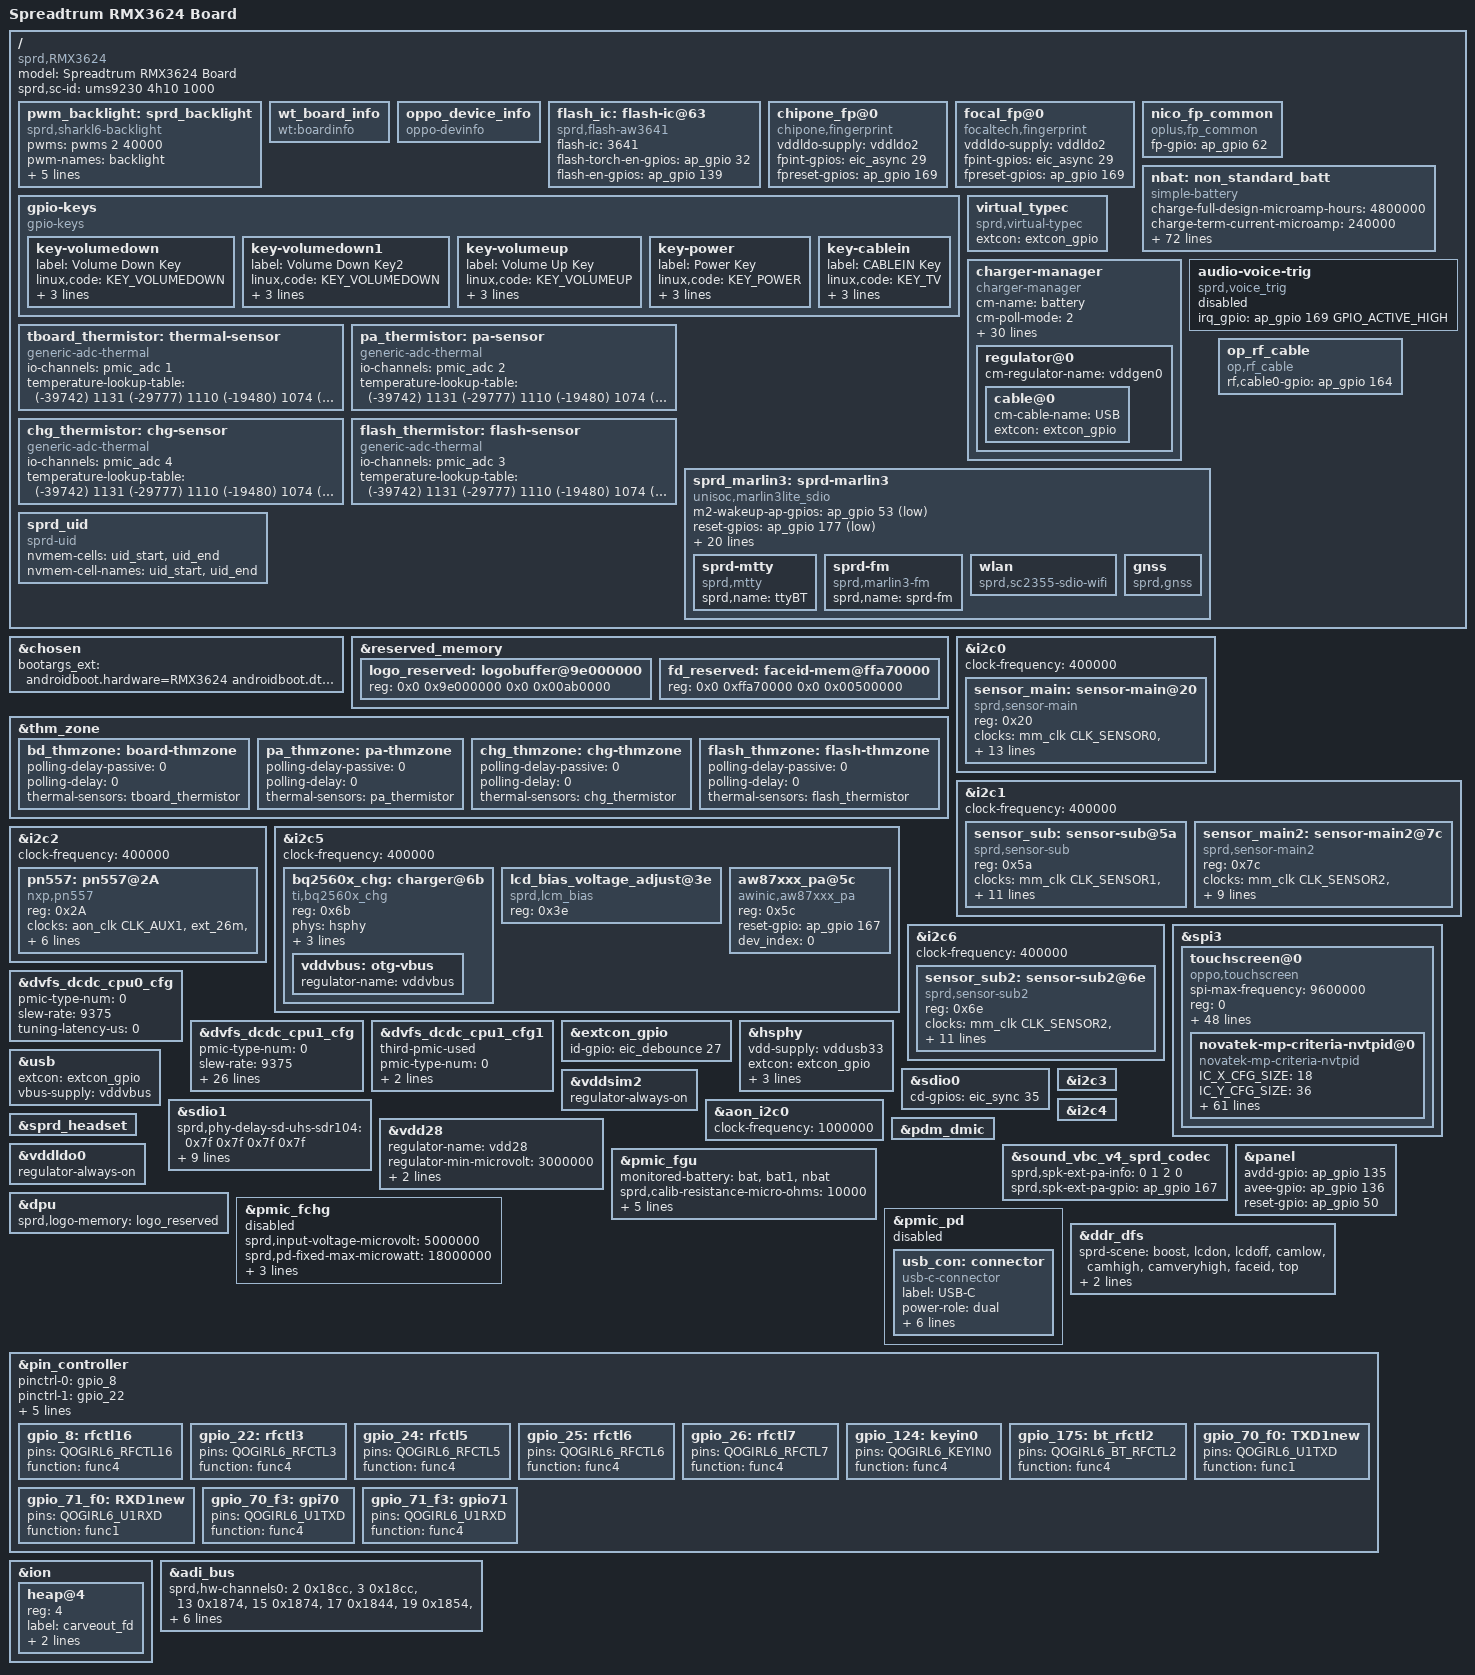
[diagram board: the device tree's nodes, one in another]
/dts-v1/;
/plugin/;
#include <dt-bindings/input/input.h>
#include <dt-bindings/gpio/gpio.h>
#include <dt-bindings/interrupt-controller/arm-gic.h>
#include <dt-bindings/clock/sprd,ums9230-clk.h>
#include <dt-bindings/mfd/sprd,sc2730-regs.h>
#include <dt-bindings/mfd/sprd,sc2730-mask.h>
#include <dt-bindings/usb/pd.h>
/*wangcong@DISPLAY.LCD 2022.06.10 modify for beidouB bring up lcd*/
#include "lcd/lcd_ili9882q_txd_mipi_hd.dtsi"
#include "lcd/lcd_icnl9911c_cw_mipi_hd.dtsi"
/*wangcong@DISPLAY.LCD 2022.06.10 modify for beidouB bring up lcd*/
/*niuhang@DISPLAY.LCD 2022.11.1 modify for beidouE bring up lcd*/
#include "lcd/lcd_icnl9911c_lc_mipi_hd.dtsi"
/*niuhang@DISPLAY.LCD 2022.11.1 modify for beidouE bring up lcd*/
/*bsp.zhoulingyun 2022.04.04 modify for bring up lcd tm*/
#include "lcd/lcd_NT36672C_csot_mipi_hd.dtsi"
#include "lcd/lcd_NT36672C_tm_mipi_hd.dtsi"
#include "lcd/lcd_g40396_truly_mipi_fhd.dtsi"
#include "lcd/lcd_dummy_mipi.dtsi"
#include "battery/RMX3624_OPLUS_LWN_4V45_5000mah.dtsi"
#include "battery/RMX3624_OPLUS_ATL_4V45_5000mah.dtsi"
/ {

	model = "Spreadtrum RMX3624 Board";

	compatible = "sprd,RMX3624";

	sprd,sc-id = "ums9230 4h10 1000";
	fragment {
		target-path = "/";
		__overlay__ {
			#address-cells = <2>;
			#size-cells = <2>;

			pwm_backlight: sprd_backlight {
				compatible = "sprd,sharkl6-backlight";
				pwms = <&pwms 2 40000>;
				pwm-names = "backlight";
				sprd,max-brightness-level = <924>;
				default-brightness-level = <262>;
				sprd,brightness-scale = <1023>;
				brightness-levels = <
							  0   3   4   5   6   7
					  8   9  10  11  12  13  14  16  17  18
					 19  20  21  22  23  24  25  26  27  28
					 29  31  33  35  37  39  41  43  45  47
					 48  50  52  54  56  58  60  62  64  67
					 69  72  74  76  78  80  82  84  86  88
					 90  92  94  96  98 100 102 104 107 109
					112 114 116 118 120 122 124 126 128 130
					132 134 136 138 140 142 144 147 149 151
					154 156 158 160 162 164 166 168 170 172
					175 178 181 184 187 190 193 196 199 203
					205 208 211 214 217 220 223 226 229 234
					237 240 243 247 250 253 256 259 263 266
					269 270 274 277 280 283 287 290 294 297
					300 303 307 310 314 318 325 329 334 339
					340 343 347 350 354 358 365 369 374 380
					382 385 389 392 396 400 407 411 416 422
					426 430 434 438 442 446 452 457 460 464
					470 474 480 486 492 498 504 508 512 516
					522 527 532 536 540 545 550 555 561 568
					574 579 584 589 594 600 605 610 615 620
					625 630 635 641 647 652 657 662 667 673
					688 694 700 706 712 716 720 725 730 735
					740 746 752 758 764 770 776 782 790 798
					803 810 817 825 832 840 845 850 855 861
					866 872 878 884 890 896 903 911 918 924
				>;
			};
			wt_board_info: wt_board_info {
				compatible = "wt:boardinfo";
				status = "okay";
			};

			oppo_device_info: oppo_device_info {
				compatible = "oppo-devinfo";
				status = "okay";
			};

			flash_ic: flash-ic@63 {
				compatible = "sprd,flash-aw3641";
				flash-ic = <3641>;
				flash-torch-en-gpios = <&ap_gpio 32 0>;
				flash-en-gpios = <&ap_gpio 139 0>;
				status = "okay";
			};
			chipone_fp@0 {
				compatible = "chipone,fingerprint";
				vddldo-supply = <&vddldo2>;
				fpint-gpios = <&eic_async 29 0 >;
				fpreset-gpios = <&ap_gpio 169 0 >;
			};

			focal_fp@0 {
				compatible = "focaltech,fingerprint";
				vddldo-supply = <&vddldo2>;
				fpint-gpios = <&eic_async 29 0 >;
				fpreset-gpios = <&ap_gpio 169 0 >;
			};

			nico_fp_common {
				compatible = "oplus,fp_common";
				fp-gpio = <&ap_gpio 62 0 >;
			};

			gpio-keys {
				compatible = "gpio-keys";

				key-volumedown {
					label = "Volume Down Key";
					linux,code = <KEY_VOLUMEDOWN>;
					gpios = <&ap_gpio 124 GPIO_ACTIVE_LOW>;
					debounce-interval = <2>;
					wakeup-source;
				};

				key-volumedown1 {
					label = "Volume Down Key2";
					linux,code = <KEY_VOLUMEDOWN>;
					gpios = <&ap_gpio 126 GPIO_ACTIVE_LOW>;
					debounce-interval = <2>;
					wakeup-source;
				};

				key-volumeup {
					label = "Volume Up Key";
					linux,code = <KEY_VOLUMEUP>;
					gpios = <&pmic_eic 4 GPIO_ACTIVE_HIGH>;
					debounce-interval = <2>;
					wakeup-source;
				};

				key-power {
					label = "Power Key";
					linux,code = <KEY_POWER>;
					gpios = <&pmic_eic 1 GPIO_ACTIVE_LOW>;
					debounce-interval = <2>;
					wakeup-source;
				};
/*wt_jiangshaokang,20220605,Add cable key detect for modem*/
				key-cablein {
					label = "CABLEIN Key";
					linux,code = <KEY_TV>;
					gpios = <&ap_gpio 164 GPIO_ACTIVE_HIGH>;
					debounce-interval = <2>;
					wakeup-source;
				};
/*wt_jiangshaokang,20220605,Add cable key detect for modem*/
			};


			nbat: non_standard_batt {
				compatible = "simple-battery";
				charge-full-design-microamp-hours = <4800000>;
				charge-term-current-microamp = <240000>;
				constant-charge-voltage-max-microvolt = <4432000>;
				factory-internal-resistance-micro-ohms = <130000>;
				voltage-min-design-microvolt = <3450000>;
				fullbatt-voltage = <4395000 4395000>;
				fullbatt-current = <260000>;
				fullbatt-track-end-vol = <4390000>;
				fullbatt-track-end-cur = <270000>;
				first-calib-voltage = <3580000>;
				first-calib-capacity = <50>;

				ir-cv-offset-microvolt = <100000>;
				ir-rc-micro-ohms = <20000>;
				ir-us-upper-limit-microvolt = <4500000>;

				ocv-capacity-celsius = <20>;
				ocv-capacity-table-0 = <4380000 100>, <4317000 95>, <4258000 90>,
							<4200000 85>, <4145000 80>, <4092000 75>,
							<4047000 70>, <3990000 65>, <3955000 60>,
							<3900000 55>, <3861000 50>, <3834000 45>,
							<3813000 40>, <3796000 35>, <3783000 30>,
							<3770000 25>, <3752000 20>, <3730000 15>,
							<3698000 10>, <3687000 5>, <3400000 0>;
				 voltage-temp-table = <1404000 650>, <1307000 700>, <1203000 750>,
							<1095000 800>, <986000 850>, <878000 900>,
							<775000 950>, <678000 1000>, <590000 1050>,
							<510000 1100>, <440000 1150>, <378000 1200>,
							<324000 1250>, <278000 1300>, <238000 1350>,
							<204000 1400>, <175000 1450>, <150000 1500>,
							<129000 1550>, <111000 1600>, <96000 1650>,
							<83000 1700>, <73000 1750>, <63000 1800>,
							<55000 1850>, <48000 1900>, <42000 1950>;
				capacity-temp-table = <45 100>, <25 100>, <10 98>, <0 93>, <(-10) 85>, <(-20) 64>;
				resistance-temp-table = <45 100>, <25 100>, <10 546>, <0 769>, <(-10) 892>, <(-20) 923>;
				charge-sdp-current-microamp = <500000 600000>;
				charge-dcp-current-microamp = <2000000 3250000>;
				charge-cdp-current-microamp = <1500000 3250000>;
				charge-unknown-current-microamp = <1200000 1200000>;
				dcp-jeita-temp-table = <900 901 0 4435000 0 4435000>,
							<1000 1030 1000000 4435000 750000 4180000>,
							<1050 1080 2250000 4435000 1250000 4435000>,
							<1120 1150 2250000 4435000 2250000 4435000>,
							<1160 1190 3250000 4435000 2250000 4180000>,
							<1450 1420 3250000 4435000 3250000 4435000>,
							<1530 1500 1250000 4130000 1250000 4130000>;
				sdp-jeita-temp-table = <900 901 0 4435000 0 4435000>,
							<1000 1030 600000 4435000 600000 4180000>,
							<1050 1080 600000 4435000 600000 4435000>,
							<1120 1150 600000 4435000 600000 4435000>,
							<1160 1190 600000 4435000 600000 4180000>,
							<1450 1420 600000 4435000 600000 4435000>,
							<1530 1500 600000 4130000 600000 4130000>;
				cdp-jeita-temp-table = <900 901 0 4435000 0 4435000>,
							<1000 1030 1000000 4435000 750000 4180000>,
							<1050 1080 2250000 4435000 1250000 4180000>,
							<1120 1150 2250000 4435000 2250000 4435000>,
							<1160 1190 3250000 4435000 2250000 4180000>,
							<1450 1420 3250000 4435000 3250000 4435000>,
							<1530 1500 1250000 4130000 1250000 4130000>;
				unknown-jeita-temp-table = <900 901 0 4435000 0 4180000>,
							<1000 1030 480000 4435000 480000 4180000>,
							<1050 1080 480000 4435000 480000 4435000>,
							<1120 1150 1000000 4435000 1000000 4435000>,
							<1160 1190 1200000 4435000 1200000 4435000>,
							<1450 1420 1200000 4435000 1200000 4435000>,
							<1530 1500 1000000 4130000 1000000 4130000>;
				force-jeita-status = <5>;
			};

			virtual_typec: virtual_typec {
				compatible = "sprd,virtual-typec";
				extcon = <&extcon_gpio>;
				status = "okay";
			};

			charger-manager {
				compatible = "charger-manager";
				cm-name = "battery";
				cm-poll-mode = <2>;
				cm-poll-interval = <5000>;
				cm-battery-stat = <2>;

				cm-fullbatt-vchkdrop-ms = <30000>;
				cm-fullbatt-vchkdrop-volt = <60000>;
				cm-fullbatt-capacity = <100>;
				/*Charge pump target charge current*/
				cm-cp-taper-current = <1000000>;

				cm-num-chargers = <1>;

				cm-chargers = "bq2560x_charger";
				cm-fuel-gauge = "sc27xx-fgu";

				/* in deci centigrade */
				cm-battery-cold = <200>;
				cm-battery-cold-in-minus;
				cm-battery-hot = <800>;
				cm-battery-temp-diff = <100>;

				/* Allow charging for 6hr */
				cm-charging-max = <72000000>;
				/* recovery charging after stop charging 45min */
				cm-discharging-max = <2700000>;

				/* the interval to feed charger watchdog */
				cm-wdt-interval = <60>;

				/* drop voltage in microVolts to allow shutdown */
				cm-shutdown-voltage = <3300000>;

				/* when 99% of the time is exceeded, it will be forced to 100% */
				cm-tickle-time-out = <1500>;

				/* how much time to allow capacity change */
				cm-one-cap-time = <15>;
				cm-thermal-zone = "board-thmzone";
				/* when the safe charging voltage is exceeded, stop charging */
				cm-charge-voltage-max = <5800000>;
				/* drop voltage in microVolts to restart charging */
				cm-charge-voltage-drop = <350000>;

				//cm-cap-remap-table = <1 2 3>, <2 3 2>, <98 99 2>, <99 100 3>;
				cm-cap-remap-table = <99 100 3>;

				monitored-battery = <&bat &bat1 &nbat>;
				cm-capacity-track;
	
				io-channels = <&pmic_adc 6>;
				io-channel-names = "bat-id-vol";

				pinctrl-names = "gpio_70_f0", "gpio_71_f0", "gpio_70_f3", "gpio_71_f3";
				pinctrl-0 = <&gpio_70_f0>;
				pinctrl-1 = <&gpio_71_f0>;
				pinctrl-2 = <&gpio_70_f3>;
				pinctrl-3 = <&gpio_71_f3>;

				regulator@0 {
					cm-regulator-name = "vddgen0";
					cable@0 {
						cm-cable-name = "USB";
						extcon = <&extcon_gpio>;
					};
				};
			};

			tboard_thermistor: thermal-sensor {
				compatible = "generic-adc-thermal";
				#thermal-sensor-cells = <0>;
				io-channels = <&pmic_adc 1>;
				io-channel-names = "sensor-channel";
				temperature-lookup-table = <
					(-39742) 1131
					(-29777) 1110
					(-19480) 1074
					(-4679) 983
					10110 838
					24805 654
					44922 413
					54903 316
					64895 238
					74884 178
					84883 133
					94883 100
					104880 75
					114889 57
					124872 43 >;
			};

			pa_thermistor: pa-sensor {
				compatible = "generic-adc-thermal";
				#thermal-sensor-cells = <0>;
				io-channels = <&pmic_adc 2>;
				io-channel-names = "sensor-channel";
				temperature-lookup-table = <
					(-39742) 1131
					(-29777) 1110
					(-19480) 1074
					(-4679) 983
					10110 838
					24805 654
					44922 413
					54903 316
					64895 238
					74884 178
					84883 133
					94883 100
					104880 75
					114889 57
					124872 43 >;
			};

			chg_thermistor: chg-sensor {
				compatible = "generic-adc-thermal";
				#thermal-sensor-cells = <0>;
				io-channels = <&pmic_adc 4>;
				io-channel-names = "sensor-channel";
				temperature-lookup-table = <
					(-39742) 1131
					(-29777) 1110
					(-19480) 1074
					(-4679) 983
					10110 838
					24805 654
					44922 413
					54903 316
					64895 238
					74884 178
					84883 133
					94883 100
					104880 75
					114889 57
					124872 43 >;
			};
			flash_thermistor: flash-sensor {
				compatible = "generic-adc-thermal";
				#thermal-sensor-cells = <0>;
				io-channels = <&pmic_adc 3>;
				io-channel-names = "sensor-channel";
				temperature-lookup-table = <
					(-39742) 1131
					(-29777) 1110
					(-19480) 1074
					(-4679) 983
					10110 838
					24805 654
					44922 413
					54903 316
					64895 238
					74884 178
					84883 133
					94883 100
					104880 75
					114889 57
					124872 43 >;
			};

			audio-voice-trig {
				status = "disable";
				compatible = "sprd,voice_trig";
				irq_gpio = <&ap_gpio 169 GPIO_ACTIVE_HIGH>;
			};

			sprd_marlin3: sprd-marlin3 {
				compatible = "unisoc,marlin3lite_sdio";
				m2-wakeup-ap-gpios = <&ap_gpio 53 GPIO_ACTIVE_LOW>;
				reset-gpios = <&ap_gpio 177 GPIO_ACTIVE_LOW>;
				enable-gpios = <&ap_gpio 116 GPIO_ACTIVE_LOW>;
				m2-to-ap-irq-gpios = <&ap_gpio 52 GPIO_ACTIVE_LOW>;
				avdd12-supply = <&vddwcn>;
				avdd33-supply = <&vddwifipa>;
				dcxo18-supply = <&vddsim2>;
				xtal-26m-clk-type = "TSX";
				clock-names = "clk_32k","source","enable";
				clocks = <&aon_clk CLK_AUX2>,
					 <&ext_32k>,
					 <&aonapb_gate CLK_AUX2_EB>;

				extcon = <&sdio1>;
				sdhci-name = <&sdio1>;
				sprd,btwf-file-name = "/dev/block/by-name/wcnmodem";
				sprd,gnss-file-name = "/vendor/firmware/gnssmodem.bin";
				adma-tx;
				adma-rx;

				/*
				 * bound parameter:
				 * [0]:addr offset, [1]:mask, [2]:unboundval, [3]:boundval
				 */
				/*avdd12-parent-bound-chip = <REG_ANA_SLP_DCDC_PD_CTRL MASK_ANA_SLP_DCDCGEN1_PD_EN 0x0 MASK_ANA_SLP_DCDCGEN1_PD_EN>;*/
				avdd12-bound-wbreq = <REG_ANA_LDO_XTL_EN10 MASK_ANA_LDO_VDDWCN_EXT_XTL3_EN 0x0 MASK_ANA_LDO_VDDWCN_EXT_XTL3_EN>;
				avdd33-bound-wbreq = <REG_ANA_LDO_XTL_EN11 MASK_ANA_LDO_VDDWIFIPA_EXT_XTL3_EN 0x0 MASK_ANA_LDO_VDDWIFIPA_EXT_XTL3_EN>;

				sprd-mtty {
					compatible = "sprd,mtty";
					sprd,name = "ttyBT";
				};

				sprd-fm {
					compatible = "sprd,marlin3-fm";
					sprd,name = "sprd-fm";
				};

				wlan {
					compatible = "sprd,sc2355-sdio-wifi";
				};

				gnss {
					compatible = "sprd,gnss";
				};
			};

			/*Used to check the RF antenna*/
			op_rf_cable {
				compatible = "op,rf_cable";
				status = "okay";
				rf,cable0-gpio = <&ap_gpio 164 GPIO_ACTIVE_HIGH>;
			};

			sprd_uid {
				compatible = "sprd-uid";
				nvmem-cells = <&uid_start>, <&uid_end>;
				nvmem-cell-names = "uid_start", "uid_end";
			};

		};
	};
};

&chosen {
	bootargs_ext = "androidboot.hardware=RMX3624 androidboot.dtbo_idx=0";
};

&reserved_memory {
	#address-cells = <2>;
	#size-cells = <2>;
	logo_reserved: logobuffer@9e000000{
		reg = <0x0 0x9e000000 0x0 0x00ab0000>;
	};

	fd_reserved: faceid-mem@ffa70000 {
		reg = <0x0 0xffa70000 0x0 0x00500000>;
	};
};

&thm_zone {

	bd_thmzone: board-thmzone {
		polling-delay-passive = <0>;
		polling-delay = <0>;
		thermal-sensors = <&tboard_thermistor>;
	};

	pa_thmzone: pa-thmzone {
		polling-delay-passive = <0>;
		polling-delay = <0>;
		thermal-sensors = <&pa_thermistor>;
	};

	chg_thmzone: chg-thmzone {
		polling-delay-passive = <0>;
		polling-delay = <0>;
		thermal-sensors = <&chg_thermistor>;
	};
	flash_thmzone: flash-thmzone {
		polling-delay-passive = <0>;
		polling-delay = <0>;
		thermal-sensors = <&flash_thermistor>;
	};

};

&i2c0 {
	status = "okay";
	clock-frequency = <400000>;
	#address-cells = <1>;
	#size-cells = <0>;

	sensor_main: sensor-main@20 {
		compatible = "sprd,sensor-main";
		reg = <0x20>;
		clock-names = "clk_src","sensor_eb",
			"clk_96m","clk_76m8",
			"clk_48m","clk_26m";
		clocks = <&mm_clk CLK_SENSOR0>,<&mm_gate CLK_MM_SENSOR0_EB>,
				<&pll1 CLK_TWPLL_96M>,<&pll1 CLK_TWPLL_76M8>,
				<&pll1 CLK_TWPLL_48M>,<&ext_26m>;
		vddio-supply = <&vddcamio>;
		vddcama-supply = <&vddcama0>;
		vddcamd-supply = <&vddcamd0>;
		vddcammot-supply = <&vddcammot>;
		dvdd-gpios = <&ap_gpio 146 0>;
		reset-gpios = <&ap_gpio 45 0>;
		power-down-gpios = <&ap_gpio 47 0>;
		sprd,phyid = <0>;
		csi = <&csi0>;
		power-domains = <&mm_domain>;
	};
};

&i2c1 {
	status = "okay";
	clock-frequency = <400000>;
	#address-cells = <1>;
	#size-cells = <0>;

	sensor_sub: sensor-sub@5a {
		compatible = "sprd,sensor-sub";
		reg = <0x5a>;
		clock-names = "clk_src","sensor_eb",
			"clk_96m","clk_76m8",
			"clk_48m","clk_26m";
		clocks = <&mm_clk CLK_SENSOR1>,<&mm_gate CLK_MM_SENSOR1_EB>,
				<&pll1 CLK_TWPLL_96M>,<&pll1 CLK_TWPLL_76M8>,
				<&pll1 CLK_TWPLL_48M>,<&ext_26m>;
		vddio-supply = <&vddcamio>;
		vddcama-supply = <&vddcama1>;
		vddcamd-supply = <&vddcamd0>;
		reset-gpios = <&ap_gpio 44 0>;
		power-down-gpios = <&ap_gpio 47 0>;
		sprd,phyid = <2>;
		csi = <&csi0>;
		power-domains = <&mm_domain>;
	};

	sensor_main2: sensor-main2@7c {
		compatible = "sprd,sensor-main2";
		reg = <0x7c>;
		clock-names = "clk_src","sensor_eb",
			"clk_96m","clk_76m8",
			"clk_48m","clk_26m";
		clocks = <&mm_clk CLK_SENSOR2>,<&mm_gate CLK_MM_SENSOR2_EB>,
				<&pll1 CLK_TWPLL_96M>,<&pll1 CLK_TWPLL_76M8>,
				<&pll1 CLK_TWPLL_48M>,<&ext_26m>;
		vddio-supply = <&vddcamio>;
		vddcama-supply = <&vddcama1>;
		reset-gpios = <&ap_gpio 47 0>;
		sprd,phyid = <4>;
		csi = <&csi2>;
		power-domains = <&mm_domain>;
	};


};

&i2c2 {
        status = "okay";
        clock-frequency = <400000>;
        #address-cells = <1>;
        #size-cells = <0>;
        pn557: pn557@2A {
                compatible = "nxp,pn557";
                reg = <0x2A>;
                clock-names = "pn557_clk","source","enable";
                clocks = <&aon_clk CLK_AUX1>, <&ext_26m>, <&aonapb_gate CLK_AUX1_EB>;
                bb-clocks = "beidouB";
                nxp,ven-gpio = <&ap_gpio 134 0>;
                nxp,irq-gpio = <&ap_gpio 30 0>;
                nxp,firm-gpio = <&ap_gpio 16 0>;
                nxp,clkreq-gpio = <&ap_gpio 15 0>;
        };
};

&i2c5 {
	status = "okay";
	clock-frequency = <400000>;
	#address-cells = <1>;
	#size-cells = <0>;

	bq2560x_chg: charger@6b {
		compatible = "ti,bq2560x_chg";
		reg = <0x6b>;
		phys = <&hsphy>;
		monitored-battery = <&bat &bat1 &nbat>;
		extcon = <&extcon_gpio>;
		/*pd-extcon-enable;*/
		irq-gpio = <&ap_gpio 115 GPIO_ACTIVE_LOW>;
		vddvbus:otg-vbus {
			regulator-name = "vddvbus";
		};
	};
	/*
	bq2597x_chg: charger@65 {
		compatible = "ti,bq2597x-standalone";
		reg = <0x65>;
		irq-gpio = <&ap_gpio 126 GPIO_ACTIVE_LOW>;

		ti,bq2597x,bus-therm-disable = <1>;
		ti,bq2597x,regulation-disable = <1>;

		ti,bq2597x,bat-ovp-threshold = <4400>;
		ti,bq2597x,bat-ovp-alarm-threshold = <4340>;
		ti,bq2597x,bat-ocp-threshold = <5500>;
		ti,bq2597x,bat-ocp-alarm-threshold = <5000>;
		ti,bq2597x,bus-ovp-threshold = <11500>;
		ti,bq2597x,bus-ovp-alarm-threshold = <10500>;
		ti,bq2597x,bus-ocp-threshold = <3000>;
		ti,bq2597x,bus-ocp-alarm-threshold = <2700>;
		ti,bq2597x,bat-ucp-alarm-threshold = <1000>;
		ti,bq2597x,bat-therm-threshold = <0x15>;
		ti,bq2597x,bus-therm-threshold = <0x15>;
		ti,bq2597x,die-therm-threshold = <0xc8>;
		ti,bq2597x,ac-ovp-threshold = <11>;
		ti,bq2597x,sense-resistor-mohm = <5>;
		ti,bq2597x,adc-sample-bits = <13>;
		ti,bq2597x,ibat-regulation-threshold = <300>;
		ti,bq2597x,vbat-regulation-threshold = <100>;
		ti,bq2597x,vdrop-threshold = <400>;
		ti,bq2597x,vdrop-deglitch = <5000>;
		ti,bq2597x,ss-timeout = <100000>;
		ti,bq2597x,watchdog-timer = <30000>;
	};

	hl1506_cp_converter: charger@1b {
		compatible = "halo,hl1506_cp_converter";
		reg = <0x1b>;
		chg_pump_en_gpio = <&ap_gpio 147 GPIO_ACTIVE_HIGH>;
	};

	nu1619_rx: charger@61 {
		compatible = "nuvolta,wl_charger_nu1619";
		reg = <0x61>;
		phys = <&hsphy>;
		rx,irq_gpio = <&ap_gpio 146 GPIO_ACTIVE_LOW>;
		switch_chg_en_gpio = <&ap_gpio 171 GPIO_ACTIVE_HIGH>;
		switch_flag_en_gpio = <&ap_gpio 176 GPIO_ACTIVE_HIGH>;
	};
	*/
	/*wangcong@DISPLAY.LCD 2022.06.10 modify for beidouB bring up lcd*/
	lcd_bias_voltage_adjust@3e {
		compatible = "sprd,lcm_bias";
		reg = <0x3e>;
	};
	/*wangcong@DISPLAY.LCD 2022.06.10 modify for beidouB bring up lcd*/

	/* AWINIC AW87XXX Smart K PA */
	aw87xxx_pa@5c {
		compatible = "awinic,aw87xxx_pa";
		reg = <0x5c>;
		reset-gpio = <&ap_gpio 167 0>;
		dev_index = < 0 >;
		status = "okay";
	};
/* AWINIC AW87XXX Smart K PA End */
};

&i2c6 {
	status = "okay";
	clock-frequency = <400000>;
	#address-cells = <1>;
	#size-cells = <0>;

	sensor_sub2: sensor-sub2@6e {
		compatible = "sprd,sensor-sub2";
		reg = <0x6e>;
		clock-names = "clk_src","sensor_eb",
			"clk_96m","clk_76m8",
			"clk_48m","clk_26m";
		clocks = <&mm_clk CLK_SENSOR2>,<&mm_gate CLK_MM_SENSOR2_EB>,
			<&pll1 CLK_TWPLL_96M>,<&pll1 CLK_TWPLL_76M8>,
			<&pll1 CLK_TWPLL_48M>,<&ext_26m>;
		vddio-supply = <&vddcamio>;
		avdd-gpios = <&ap_gpio 130 0>;
		vddcamd-supply = <&vddcamd1>;
		vddcammot-supply = <&vddcammot>;
		mot-gpios = <&ap_gpio 112 0>;
		reset-gpios = <&ap_gpio 114 0>;
	/*	power-down-gpios = <&ap_gpio 40 0>;*/
		sprd,phyid = <3>;
		csi = <&csi2>;
	};
};

&spi3 {
	status = "okay";
	#address-cells = <1>;
	#size-cells = <0>;


	touchscreen@0 {
			compatible = "oppo,touchscreen";
			spi-max-frequency = <9600000>;
			reg = <0>;
			touch,irq-gpio = <&eic_async 16 GPIO_ACTIVE_HIGH>;
			touch,rst-gpio = <&ap_gpio 145 GPIO_ACTIVE_HIGH>;
			touch,panel-coords = <0 720 0 1600>;
			chipone,x-res = <720>;
			chipone,y-res = <1600>;

                        /* Charger detect */
                        chipone,touch-charger-detect-enable;
                        chipone,touch-charger-detect-type = "notify"; /* notify, poll */
                        chipone,touch-charger-detect-psy-name = "battery";
                        chipone,touch-charger-detect-psp = "POWER_SUPPLY_PROP_ONLINE";
                        chipone,touch-charger-detect-psp-poll-interval = <1000>;

                        /* Earjack detect */
                        chipone,touch-earjack-detect-enable;
                        /* MTK:  /sys/bus/platform/drivers/Accdet_Driver/state,
                           Sprd: /sys/kernel/headset/state
                           QCOM: None, and disable it */
                        chipone,touch-earjack-state-filepath = "/sys/bus/platform/drivers/Accdet_Driver/state";
                        chipone,touch-earjack-poll-interval = <1000>;
		                chipone,test-reset-pin ;
		                chipone,test-int-pin ;
		                chipone,test-rawdata ;
		                chipone,test-rawdata-frames      = <1>;
		                chipone,rawdata-min              = <1500>;
		                chipone,rawdata-max              = <3000>;
		                chipone,test-noise;
		                chipone,test-noise-frames        = <50>;
		                chipone,noise-max                = <100>;
		                chipone,test-open;
		                chipone,open-min                 = <2800>;
		                chipone,test-short;
		                chipone,short-min = <350>;
		                chipone,test-compensate-cap;
		                chipone,compensate-cap-min = <1>;
		                chipone,compensate-cap-max = <126>;

		                /* gesture data test */
		                chipone,test-gesture-rawdata;
		                chipone,test-gesture-rawdata-frames = <1>;
		                chipone,gesture-rawdata-min = <950>;
		                chipone,gesture-rawdata-max = <2750>;

		                chipone,test-gesture-lp-rawdata;
		                chipone,test-gesture-lp-rawdata-frames = <1>;
		                chipone,gesture-lp-rawdata-min = <950>;
		                chipone,gesture-lp-rawdata-max = <2800>;

		                chipone,test-gesture-noise;
		                chipone,test-gesture-noise-frames = <50>;
		                chipone,gesture-noise-max = <95>;

		                chipone,test-gesture-lp-noise;
		                chipone,test-gesture-lp-noise-frames = <50>;
		                chipone,gesture-lp-noise-max = <73>;

		//for novatek
		//novatek,pen-support;
		//novatek,stylus-resol-double;

		/* 525 */
		//novatek,swrst-n8-addr = <0x01F01A>;

		/* 672A, 525B, 675, 526, 672C, 523 */
		novatek,swrst-n8-addr = <0x03F0FE>;
		novatek,spi-rd-fast-addr = <0x03F310>;

		/* MP */
		//novatek,mp-support-dt;

		novatek-mp-criteria-nvtpid@0 {
			#address-cells = <1>;
			#size-cells = <0>;
			compatible = "novatek-mp-criteria-nvtpid";

			/* MP Config */
			IC_X_CFG_SIZE = <18>;
			IC_Y_CFG_SIZE = <36>;
			IC_KEY_CFG_SIZE = <4>;
			X_Channel = <18>;
			Y_Channel = <36>;
			AIN_X = <0 1 2 3 4 5 6 7 8 9 10 11 12 13 14 15 16 17>;
			AIN_Y = <0 1 2 3 4 5 6 7 8 9 10 11 12 13 14 15 16 17 18 19 20 21 22 23 24 25 26 27 28 29 30 31 32 33 34 35>;
			//AIN_X = <0 1 2 3 4 5 6 7 8 9 10 11 12 13 14 15 16 17 18 19 20 21 22 23 24 25 26 27 28 29 30 31>;
			//AIN_Y = <0 1 2 3 4 5 6 7 8 9 10 11 12 13 14 15 16 17 18 19 20 21 22 23 24 25 26 27 28 29 30 31 32 33 34 35 36 37 38 39 40 41 42 43 44 45 46 47 48 49>;
			AIN_KEY = <0 1 2 0xFF>;

			/* MP Criteria */
			PS_Config_Lmt_Short_Rawdata_P = <
				14008 14008 14008 14008 14008 14008 14008 14008 14008 14008 14008 14008 14008 14008 14008 14008 14008 14008 14008 14008 14008 14008 14008 14008 14008 14008 14008 14008 14008 14008 14008 14008
				14008 14008 14008 14008 14008 14008 14008 14008 14008 14008 14008 14008 14008 14008 14008 14008 14008 14008 14008 14008 14008 14008 14008 14008 14008 14008 14008 14008 14008 14008 14008 14008
				14008 14008 14008 14008 14008 14008 14008 14008 14008 14008 14008 14008 14008 14008 14008 14008 14008 14008 14008 14008 14008 14008 14008 14008 14008 14008 14008 14008 14008 14008 14008 14008
				14008 14008 14008 14008 14008 14008 14008 14008 14008 14008 14008 14008 14008 14008 14008 14008 14008 14008 14008 14008 14008 14008 14008 14008 14008 14008 14008 14008 14008 14008 14008 14008
				14008 14008 14008 14008 14008 14008 14008 14008 14008 14008 14008 14008 14008 14008 14008 14008 14008 14008 14008 14008 14008 14008 14008 14008 14008 14008 14008 14008 14008 14008 14008 14008
				14008 14008 14008 14008 14008 14008 14008 14008 14008 14008 14008 14008 14008 14008 14008 14008 14008 14008 14008 14008 14008 14008 14008 14008 14008 14008 14008 14008 14008 14008 14008 14008
				14008 14008 14008 14008 14008 14008 14008 14008 14008 14008 14008 14008 14008 14008 14008 14008 14008 14008 14008 14008 14008 14008 14008 14008 14008 14008 14008 14008 14008 14008 14008 14008
				14008 14008 14008 14008 14008 14008 14008 14008 14008 14008 14008 14008 14008 14008 14008 14008 14008 14008 14008 14008 14008 14008 14008 14008 14008 14008 14008 14008 14008 14008 14008 14008
				14008 14008 14008 14008 14008 14008 14008 14008 14008 14008 14008 14008 14008 14008 14008 14008 14008 14008 14008 14008 14008 14008 14008 14008 14008 14008 14008 14008 14008 14008 14008 14008
				14008 14008 14008 14008 14008 14008 14008 14008 14008 14008 14008 14008 14008 14008 14008 14008 14008 14008 14008 14008 14008 14008 14008 14008 14008 14008 14008 14008 14008 14008 14008 14008
				14008 14008 14008 14008 14008 14008 14008 14008 14008 14008 14008 14008 14008 14008 14008 14008 14008 14008 14008 14008 14008 14008 14008 14008 14008 14008 14008 14008 14008 14008 14008 14008
				14008 14008 14008 14008 14008 14008 14008 14008 14008 14008 14008 14008 14008 14008 14008 14008 14008 14008 14008 14008 14008 14008 14008 14008 14008 14008 14008 14008 14008 14008 14008 14008
				14008 14008 14008 14008 14008 14008 14008 14008 14008 14008 14008 14008 14008 14008 14008 14008 14008 14008 14008 14008 14008 14008 14008 14008 14008 14008 14008 14008 14008 14008 14008 14008
				14008 14008 14008 14008 14008 14008 14008 14008 14008 14008 14008 14008 14008 14008 14008 14008 14008 14008 14008 14008 14008 14008 14008 14008 14008 14008 14008 14008 14008 14008 14008 14008
				14008 14008 14008 14008 14008 14008 14008 14008 14008 14008 14008 14008 14008 14008 14008 14008 14008 14008 14008 14008 14008 14008 14008 14008 14008 14008 14008 14008 14008 14008 14008 14008
				14008 14008 14008 14008 14008 14008 14008 14008 14008 14008 14008 14008 14008 14008 14008 14008 14008 14008 14008 14008 14008 14008 14008 14008 14008 14008 14008 14008 14008 14008 14008 14008
				14008 14008 14008 14008 14008 14008 14008 14008 14008 14008 14008 14008 14008 14008 14008 14008 14008 14008 14008 14008 14008 14008 14008 14008 14008 14008 14008 14008 14008 14008 14008 14008
				14008 14008 14008 14008 14008 14008 14008 14008 14008 14008 14008 14008 14008 14008 14008 14008 14008 14008 14008 14008 14008 14008 14008 14008 14008 14008 14008 14008 14008 14008 14008 14008
				14008 14008 14008 14008 14008 14008 14008 14008 14008 14008 14008 14008 14008 14008 14008 14008 14008 14008 14008 14008 14008 14008 14008 14008 14008 14008 14008 14008 14008 14008 14008 14008
				14008 14008 14008 14008 14008 14008 14008 14008 14008 14008 14008 14008 14008 14008 14008 14008 14008 14008 14008 14008 14008 14008 14008 14008 14008 14008 14008 14008 14008 14008 14008 14008
				14008 14008 14008 14008 14008 14008 14008 14008 14008 14008 14008 14008 14008 14008 14008 14008 14008 14008 14008 14008 14008 14008 14008 14008 14008 14008 14008 14008 14008 14008 14008 14008
				14008 14008 14008 14008 14008 14008 14008 14008 14008 14008 14008 14008 14008 14008 14008 14008 14008 14008 14008 14008 14008 14008 14008 14008 14008 14008 14008 14008 14008 14008 14008 14008
				14008 14008 14008 14008 14008 14008 14008 14008 14008 14008 14008 14008 14008 14008 14008 14008 14008 14008 14008 14008 14008 14008 14008 14008 14008 14008 14008 14008 14008 14008 14008 14008
				14008 14008 14008 14008 14008 14008 14008 14008 14008 14008 14008 14008 14008 14008 14008 14008 14008 14008 14008 14008 14008 14008 14008 14008 14008 14008 14008 14008 14008 14008 14008 14008
				14008 14008 14008 14008 14008 14008 14008 14008 14008 14008 14008 14008 14008 14008 14008 14008 14008 14008 14008 14008 14008 14008 14008 14008 14008 14008 14008 14008 14008 14008 14008 14008
				14008 14008 14008 14008 14008 14008 14008 14008 14008 14008 14008 14008 14008 14008 14008 14008 14008 14008 14008 14008 14008 14008 14008 14008 14008 14008 14008 14008 14008 14008 14008 14008
				14008 14008 14008 14008 14008 14008 14008 14008 14008 14008 14008 14008 14008 14008 14008 14008 14008 14008 14008 14008 14008 14008 14008 14008 14008 14008 14008 14008 14008 14008 14008 14008
				14008 14008 14008 14008 14008 14008 14008 14008 14008 14008 14008 14008 14008 14008 14008 14008 14008 14008 14008 14008 14008 14008 14008 14008 14008 14008 14008 14008 14008 14008 14008 14008
				14008 14008 14008 14008 14008 14008 14008 14008 14008 14008 14008 14008 14008 14008 14008 14008 14008 14008 14008 14008 14008 14008 14008 14008 14008 14008 14008 14008 14008 14008 14008 14008
				14008 14008 14008 14008 14008 14008 14008 14008 14008 14008 14008 14008 14008 14008 14008 14008 14008 14008 14008 14008 14008 14008 14008 14008 14008 14008 14008 14008 14008 14008 14008 14008
				14008 14008 14008 14008 14008 14008 14008 14008 14008 14008 14008 14008 14008 14008 14008 14008 14008 14008 14008 14008 14008 14008 14008 14008 14008 14008 14008 14008 14008 14008 14008 14008
				14008 14008 14008 14008 14008 14008 14008 14008 14008 14008 14008 14008 14008 14008 14008 14008 14008 14008 14008 14008 14008 14008 14008 14008 14008 14008 14008 14008 14008 14008 14008 14008
				14008 14008 14008 14008 14008 14008 14008 14008 14008 14008 14008 14008 14008 14008 14008 14008 14008 14008 14008 14008 14008 14008 14008 14008 14008 14008 14008 14008 14008 14008 14008 14008
				14008 14008 14008 14008 14008 14008 14008 14008 14008 14008 14008 14008 14008 14008 14008 14008 14008 14008 14008 14008 14008 14008 14008 14008 14008 14008 14008 14008 14008 14008 14008 14008
				14008 14008 14008 14008 14008 14008 14008 14008 14008 14008 14008 14008 14008 14008 14008 14008 14008 14008 14008 14008 14008 14008 14008 14008 14008 14008 14008 14008 14008 14008 14008 14008
				14008 14008 14008 14008 14008 14008 14008 14008 14008 14008 14008 14008 14008 14008 14008 14008 14008 14008 14008 14008 14008 14008 14008 14008 14008 14008 14008 14008 14008 14008 14008 14008
				14008 14008 14008 14008 14008 14008 14008 14008 14008 14008 14008 14008 14008 14008 14008 14008 14008 14008 14008 14008 14008 14008 14008 14008 14008 14008 14008 14008 14008 14008 14008 14008
				14008 14008 14008 14008 14008 14008 14008 14008 14008 14008 14008 14008 14008 14008 14008 14008 14008 14008 14008 14008 14008 14008 14008 14008 14008 14008 14008 14008 14008 14008 14008 14008
				14008 14008 14008 14008 14008 14008 14008 14008 14008 14008 14008 14008 14008 14008 14008 14008 14008 14008 14008 14008 14008 14008 14008 14008 14008 14008 14008 14008 14008 14008 14008 14008
				14008 14008 14008 14008 14008 14008 14008 14008 14008 14008 14008 14008 14008 14008 14008 14008 14008 14008 14008 14008 14008 14008 14008 14008 14008 14008 14008 14008 14008 14008 14008 14008
				14008 14008 14008 14008 14008 14008 14008 14008 14008 14008 14008 14008 14008 14008 14008 14008 14008 14008 14008 14008 14008 14008 14008 14008 14008 14008 14008 14008 14008 14008 14008 14008
				14008 14008 14008 14008 14008 14008 14008 14008 14008 14008 14008 14008 14008 14008 14008 14008 14008 14008 14008 14008 14008 14008 14008 14008 14008 14008 14008 14008 14008 14008 14008 14008
				14008 14008 14008 14008 14008 14008 14008 14008 14008 14008 14008 14008 14008 14008 14008 14008 14008 14008 14008 14008 14008 14008 14008 14008 14008 14008 14008 14008 14008 14008 14008 14008
				14008 14008 14008 14008 14008 14008 14008 14008 14008 14008 14008 14008 14008 14008 14008 14008 14008 14008 14008 14008 14008 14008 14008 14008 14008 14008 14008 14008 14008 14008 14008 14008
				14008 14008 14008 14008 14008 14008 14008 14008 14008 14008 14008 14008 14008 14008 14008 14008 14008 14008 14008 14008 14008 14008 14008 14008 14008 14008 14008 14008 14008 14008 14008 14008
				14008 14008 14008 14008 14008 14008 14008 14008 14008 14008 14008 14008 14008 14008 14008 14008 14008 14008 14008 14008 14008 14008 14008 14008 14008 14008 14008 14008 14008 14008 14008 14008
				14008 14008 14008 14008 14008 14008 14008 14008 14008 14008 14008 14008 14008 14008 14008 14008 14008 14008 14008 14008 14008 14008 14008 14008 14008 14008 14008 14008 14008 14008 14008 14008
				14008 14008 14008 14008 14008 14008 14008 14008 14008 14008 14008 14008 14008 14008 14008 14008 14008 14008 14008 14008 14008 14008 14008 14008 14008 14008 14008 14008 14008 14008 14008 14008
				14008 14008 14008 14008 14008 14008 14008 14008 14008 14008 14008 14008 14008 14008 14008 14008 14008 14008 14008 14008 14008 14008 14008 14008 14008 14008 14008 14008 14008 14008 14008 14008
				14008 14008 14008 14008 14008 14008 14008 14008 14008 14008 14008 14008 14008 14008 14008 14008 14008 14008 14008 14008 14008 14008 14008 14008 14008 14008 14008 14008 14008 14008 14008 14008
				14008 14008 14008>;

			PS_Config_Lmt_Short_Rawdata_N = <
				10000 10000 10000 10000 10000 10000 10000 10000 10000 10000 10000 10000 10000 10000 10000 10000 10000 10000 10000 10000 10000 10000 10000 10000 10000 10000 10000 10000 10000 10000 10000 10000
				10000 10000 10000 10000 10000 10000 10000 10000 10000 10000 10000 10000 10000 10000 10000 10000 10000 10000 10000 10000 10000 10000 10000 10000 10000 10000 10000 10000 10000 10000 10000 10000
				10000 10000 10000 10000 10000 10000 10000 10000 10000 10000 10000 10000 10000 10000 10000 10000 10000 10000 10000 10000 10000 10000 10000 10000 10000 10000 10000 10000 10000 10000 10000 10000
				10000 10000 10000 10000 10000 10000 10000 10000 10000 10000 10000 10000 10000 10000 10000 10000 10000 10000 10000 10000 10000 10000 10000 10000 10000 10000 10000 10000 10000 10000 10000 10000
				10000 10000 10000 10000 10000 10000 10000 10000 10000 10000 10000 10000 10000 10000 10000 10000 10000 10000 10000 10000 10000 10000 10000 10000 10000 10000 10000 10000 10000 10000 10000 10000
				10000 10000 10000 10000 10000 10000 10000 10000 10000 10000 10000 10000 10000 10000 10000 10000 10000 10000 10000 10000 10000 10000 10000 10000 10000 10000 10000 10000 10000 10000 10000 10000
				10000 10000 10000 10000 10000 10000 10000 10000 10000 10000 10000 10000 10000 10000 10000 10000 10000 10000 10000 10000 10000 10000 10000 10000 10000 10000 10000 10000 10000 10000 10000 10000
				10000 10000 10000 10000 10000 10000 10000 10000 10000 10000 10000 10000 10000 10000 10000 10000 10000 10000 10000 10000 10000 10000 10000 10000 10000 10000 10000 10000 10000 10000 10000 10000
				10000 10000 10000 10000 10000 10000 10000 10000 10000 10000 10000 10000 10000 10000 10000 10000 10000 10000 10000 10000 10000 10000 10000 10000 10000 10000 10000 10000 10000 10000 10000 10000
				10000 10000 10000 10000 10000 10000 10000 10000 10000 10000 10000 10000 10000 10000 10000 10000 10000 10000 10000 10000 10000 10000 10000 10000 10000 10000 10000 10000 10000 10000 10000 10000
				10000 10000 10000 10000 10000 10000 10000 10000 10000 10000 10000 10000 10000 10000 10000 10000 10000 10000 10000 10000 10000 10000 10000 10000 10000 10000 10000 10000 10000 10000 10000 10000
				10000 10000 10000 10000 10000 10000 10000 10000 10000 10000 10000 10000 10000 10000 10000 10000 10000 10000 10000 10000 10000 10000 10000 10000 10000 10000 10000 10000 10000 10000 10000 10000
				10000 10000 10000 10000 10000 10000 10000 10000 10000 10000 10000 10000 10000 10000 10000 10000 10000 10000 10000 10000 10000 10000 10000 10000 10000 10000 10000 10000 10000 10000 10000 10000
				10000 10000 10000 10000 10000 10000 10000 10000 10000 10000 10000 10000 10000 10000 10000 10000 10000 10000 10000 10000 10000 10000 10000 10000 10000 10000 10000 10000 10000 10000 10000 10000
				10000 10000 10000 10000 10000 10000 10000 10000 10000 10000 10000 10000 10000 10000 10000 10000 10000 10000 10000 10000 10000 10000 10000 10000 10000 10000 10000 10000 10000 10000 10000 10000
				10000 10000 10000 10000 10000 10000 10000 10000 10000 10000 10000 10000 10000 10000 10000 10000 10000 10000 10000 10000 10000 10000 10000 10000 10000 10000 10000 10000 10000 10000 10000 10000
				10000 10000 10000 10000 10000 10000 10000 10000 10000 10000 10000 10000 10000 10000 10000 10000 10000 10000 10000 10000 10000 10000 10000 10000 10000 10000 10000 10000 10000 10000 10000 10000
				10000 10000 10000 10000 10000 10000 10000 10000 10000 10000 10000 10000 10000 10000 10000 10000 10000 10000 10000 10000 10000 10000 10000 10000 10000 10000 10000 10000 10000 10000 10000 10000
				10000 10000 10000 10000 10000 10000 10000 10000 10000 10000 10000 10000 10000 10000 10000 10000 10000 10000 10000 10000 10000 10000 10000 10000 10000 10000 10000 10000 10000 10000 10000 10000
				10000 10000 10000 10000 10000 10000 10000 10000 10000 10000 10000 10000 10000 10000 10000 10000 10000 10000 10000 10000 10000 10000 10000 10000 10000 10000 10000 10000 10000 10000 10000 10000
				10000 10000 10000 10000 10000 10000 10000 10000 10000 10000 10000 10000 10000 10000 10000 10000 10000 10000 10000 10000 10000 10000 10000 10000 10000 10000 10000 10000 10000 10000 10000 10000
				10000 10000 10000 10000 10000 10000 10000 10000 10000 10000 10000 10000 10000 10000 10000 10000 10000 10000 10000 10000 10000 10000 10000 10000 10000 10000 10000 10000 10000 10000 10000 10000
				10000 10000 10000 10000 10000 10000 10000 10000 10000 10000 10000 10000 10000 10000 10000 10000 10000 10000 10000 10000 10000 10000 10000 10000 10000 10000 10000 10000 10000 10000 10000 10000
				10000 10000 10000 10000 10000 10000 10000 10000 10000 10000 10000 10000 10000 10000 10000 10000 10000 10000 10000 10000 10000 10000 10000 10000 10000 10000 10000 10000 10000 10000 10000 10000
				10000 10000 10000 10000 10000 10000 10000 10000 10000 10000 10000 10000 10000 10000 10000 10000 10000 10000 10000 10000 10000 10000 10000 10000 10000 10000 10000 10000 10000 10000 10000 10000
				10000 10000 10000 10000 10000 10000 10000 10000 10000 10000 10000 10000 10000 10000 10000 10000 10000 10000 10000 10000 10000 10000 10000 10000 10000 10000 10000 10000 10000 10000 10000 10000
				10000 10000 10000 10000 10000 10000 10000 10000 10000 10000 10000 10000 10000 10000 10000 10000 10000 10000 10000 10000 10000 10000 10000 10000 10000 10000 10000 10000 10000 10000 10000 10000
				10000 10000 10000 10000 10000 10000 10000 10000 10000 10000 10000 10000 10000 10000 10000 10000 10000 10000 10000 10000 10000 10000 10000 10000 10000 10000 10000 10000 10000 10000 10000 10000
				10000 10000 10000 10000 10000 10000 10000 10000 10000 10000 10000 10000 10000 10000 10000 10000 10000 10000 10000 10000 10000 10000 10000 10000 10000 10000 10000 10000 10000 10000 10000 10000
				10000 10000 10000 10000 10000 10000 10000 10000 10000 10000 10000 10000 10000 10000 10000 10000 10000 10000 10000 10000 10000 10000 10000 10000 10000 10000 10000 10000 10000 10000 10000 10000
				10000 10000 10000 10000 10000 10000 10000 10000 10000 10000 10000 10000 10000 10000 10000 10000 10000 10000 10000 10000 10000 10000 10000 10000 10000 10000 10000 10000 10000 10000 10000 10000
				10000 10000 10000 10000 10000 10000 10000 10000 10000 10000 10000 10000 10000 10000 10000 10000 10000 10000 10000 10000 10000 10000 10000 10000 10000 10000 10000 10000 10000 10000 10000 10000
				10000 10000 10000 10000 10000 10000 10000 10000 10000 10000 10000 10000 10000 10000 10000 10000 10000 10000 10000 10000 10000 10000 10000 10000 10000 10000 10000 10000 10000 10000 10000 10000
				10000 10000 10000 10000 10000 10000 10000 10000 10000 10000 10000 10000 10000 10000 10000 10000 10000 10000 10000 10000 10000 10000 10000 10000 10000 10000 10000 10000 10000 10000 10000 10000
				10000 10000 10000 10000 10000 10000 10000 10000 10000 10000 10000 10000 10000 10000 10000 10000 10000 10000 10000 10000 10000 10000 10000 10000 10000 10000 10000 10000 10000 10000 10000 10000
				10000 10000 10000 10000 10000 10000 10000 10000 10000 10000 10000 10000 10000 10000 10000 10000 10000 10000 10000 10000 10000 10000 10000 10000 10000 10000 10000 10000 10000 10000 10000 10000
				10000 10000 10000 10000 10000 10000 10000 10000 10000 10000 10000 10000 10000 10000 10000 10000 10000 10000 10000 10000 10000 10000 10000 10000 10000 10000 10000 10000 10000 10000 10000 10000
				10000 10000 10000 10000 10000 10000 10000 10000 10000 10000 10000 10000 10000 10000 10000 10000 10000 10000 10000 10000 10000 10000 10000 10000 10000 10000 10000 10000 10000 10000 10000 10000
				10000 10000 10000 10000 10000 10000 10000 10000 10000 10000 10000 10000 10000 10000 10000 10000 10000 10000 10000 10000 10000 10000 10000 10000 10000 10000 10000 10000 10000 10000 10000 10000
				10000 10000 10000 10000 10000 10000 10000 10000 10000 10000 10000 10000 10000 10000 10000 10000 10000 10000 10000 10000 10000 10000 10000 10000 10000 10000 10000 10000 10000 10000 10000 10000
				10000 10000 10000 10000 10000 10000 10000 10000 10000 10000 10000 10000 10000 10000 10000 10000 10000 10000 10000 10000 10000 10000 10000 10000 10000 10000 10000 10000 10000 10000 10000 10000
				10000 10000 10000 10000 10000 10000 10000 10000 10000 10000 10000 10000 10000 10000 10000 10000 10000 10000 10000 10000 10000 10000 10000 10000 10000 10000 10000 10000 10000 10000 10000 10000
				10000 10000 10000 10000 10000 10000 10000 10000 10000 10000 10000 10000 10000 10000 10000 10000 10000 10000 10000 10000 10000 10000 10000 10000 10000 10000 10000 10000 10000 10000 10000 10000
				10000 10000 10000 10000 10000 10000 10000 10000 10000 10000 10000 10000 10000 10000 10000 10000 10000 10000 10000 10000 10000 10000 10000 10000 10000 10000 10000 10000 10000 10000 10000 10000
				10000 10000 10000 10000 10000 10000 10000 10000 10000 10000 10000 10000 10000 10000 10000 10000 10000 10000 10000 10000 10000 10000 10000 10000 10000 10000 10000 10000 10000 10000 10000 10000
				10000 10000 10000 10000 10000 10000 10000 10000 10000 10000 10000 10000 10000 10000 10000 10000 10000 10000 10000 10000 10000 10000 10000 10000 10000 10000 10000 10000 10000 10000 10000 10000
				10000 10000 10000 10000 10000 10000 10000 10000 10000 10000 10000 10000 10000 10000 10000 10000 10000 10000 10000 10000 10000 10000 10000 10000 10000 10000 10000 10000 10000 10000 10000 10000
				10000 10000 10000 10000 10000 10000 10000 10000 10000 10000 10000 10000 10000 10000 10000 10000 10000 10000 10000 10000 10000 10000 10000 10000 10000 10000 10000 10000 10000 10000 10000 10000
				10000 10000 10000 10000 10000 10000 10000 10000 10000 10000 10000 10000 10000 10000 10000 10000 10000 10000 10000 10000 10000 10000 10000 10000 10000 10000 10000 10000 10000 10000 10000 10000
				10000 10000 10000 10000 10000 10000 10000 10000 10000 10000 10000 10000 10000 10000 10000 10000 10000 10000 10000 10000 10000 10000 10000 10000 10000 10000 10000 10000 10000 10000 10000 10000
				10000 10000 10000>;

			PS_Config_Lmt_Open_Rawdata_P = <
				5120 5120 5120 5120 5120 5120 5120 5120 5120 5120 5120 5120 5120 5120 5120 5120 5120 5120 5120 5120 5120 5120 5120 5120 5120 5120 5120 5120 5120 5120 5120 5120
				5120 5120 5120 5120 5120 5120 5120 5120 5120 5120 5120 5120 5120 5120 5120 5120 5120 5120 5120 5120 5120 5120 5120 5120 5120 5120 5120 5120 5120 5120 5120 5120
				5120 5120 5120 5120 5120 5120 5120 5120 5120 5120 5120 5120 5120 5120 5120 5120 5120 5120 5120 5120 5120 5120 5120 5120 5120 5120 5120 5120 5120 5120 5120 5120
				5120 5120 5120 5120 5120 5120 5120 5120 5120 5120 5120 5120 5120 5120 5120 5120 5120 5120 5120 5120 5120 5120 5120 5120 5120 5120 5120 5120 5120 5120 5120 5120
				5120 5120 5120 5120 5120 5120 5120 5120 5120 5120 5120 5120 5120 5120 5120 5120 5120 5120 5120 5120 5120 5120 5120 5120 5120 5120 5120 5120 5120 5120 5120 5120
				5120 5120 5120 5120 5120 5120 5120 5120 5120 5120 5120 5120 5120 5120 5120 5120 5120 5120 5120 5120 5120 5120 5120 5120 5120 5120 5120 5120 5120 5120 5120 5120
				5120 5120 5120 5120 5120 5120 5120 5120 5120 5120 5120 5120 5120 5120 5120 5120 5120 5120 5120 5120 5120 5120 5120 5120 5120 5120 5120 5120 5120 5120 5120 5120
				5120 5120 5120 5120 5120 5120 5120 5120 5120 5120 5120 5120 5120 5120 5120 5120 5120 5120 5120 5120 5120 5120 5120 5120 5120 5120 5120 5120 5120 5120 5120 5120
				5120 5120 5120 5120 5120 5120 5120 5120 5120 5120 5120 5120 5120 5120 5120 5120 5120 5120 5120 5120 5120 5120 5120 5120 5120 5120 5120 5120 5120 5120 5120 5120
				5120 5120 5120 5120 5120 5120 5120 5120 5120 5120 5120 5120 5120 5120 5120 5120 5120 5120 5120 5120 5120 5120 5120 5120 5120 5120 5120 5120 5120 5120 5120 5120
				5120 5120 5120 5120 5120 5120 5120 5120 5120 5120 5120 5120 5120 5120 5120 5120 5120 5120 5120 5120 5120 5120 5120 5120 5120 5120 5120 5120 5120 5120 5120 5120
				5120 5120 5120 5120 5120 5120 5120 5120 5120 5120 5120 5120 5120 5120 5120 5120 5120 5120 5120 5120 5120 5120 5120 5120 5120 5120 5120 5120 5120 5120 5120 5120
				5120 5120 5120 5120 5120 5120 5120 5120 5120 5120 5120 5120 5120 5120 5120 5120 5120 5120 5120 5120 5120 5120 5120 5120 5120 5120 5120 5120 5120 5120 5120 5120
				5120 5120 5120 5120 5120 5120 5120 5120 5120 5120 5120 5120 5120 5120 5120 5120 5120 5120 5120 5120 5120 5120 5120 5120 5120 5120 5120 5120 5120 5120 5120 5120
				5120 5120 5120 5120 5120 5120 5120 5120 5120 5120 5120 5120 5120 5120 5120 5120 5120 5120 5120 5120 5120 5120 5120 5120 5120 5120 5120 5120 5120 5120 5120 5120
				5120 5120 5120 5120 5120 5120 5120 5120 5120 5120 5120 5120 5120 5120 5120 5120 5120 5120 5120 5120 5120 5120 5120 5120 5120 5120 5120 5120 5120 5120 5120 5120
				5120 5120 5120 5120 5120 5120 5120 5120 5120 5120 5120 5120 5120 5120 5120 5120 5120 5120 5120 5120 5120 5120 5120 5120 5120 5120 5120 5120 5120 5120 5120 5120
				5120 5120 5120 5120 5120 5120 5120 5120 5120 5120 5120 5120 5120 5120 5120 5120 5120 5120 5120 5120 5120 5120 5120 5120 5120 5120 5120 5120 5120 5120 5120 5120
				5120 5120 5120 5120 5120 5120 5120 5120 5120 5120 5120 5120 5120 5120 5120 5120 5120 5120 5120 5120 5120 5120 5120 5120 5120 5120 5120 5120 5120 5120 5120 5120
				5120 5120 5120 5120 5120 5120 5120 5120 5120 5120 5120 5120 5120 5120 5120 5120 5120 5120 5120 5120 5120 5120 5120 5120 5120 5120 5120 5120 5120 5120 5120 5120
				5120 5120 5120 5120 5120 5120 5120 5120 5120 5120 5120 5120 5120 5120 5120 5120 5120 5120 5120 5120 5120 5120 5120 5120 5120 5120 5120 5120 5120 5120 5120 5120
				5120 5120 5120 5120 5120 5120 5120 5120 5120 5120 5120 5120 5120 5120 5120 5120 5120 5120 5120 5120 5120 5120 5120 5120 5120 5120 5120 5120 5120 5120 5120 5120
				5120 5120 5120 5120 5120 5120 5120 5120 5120 5120 5120 5120 5120 5120 5120 5120 5120 5120 5120 5120 5120 5120 5120 5120 5120 5120 5120 5120 5120 5120 5120 5120
				5120 5120 5120 5120 5120 5120 5120 5120 5120 5120 5120 5120 5120 5120 5120 5120 5120 5120 5120 5120 5120 5120 5120 5120 5120 5120 5120 5120 5120 5120 5120 5120
				5120 5120 5120 5120 5120 5120 5120 5120 5120 5120 5120 5120 5120 5120 5120 5120 5120 5120 5120 5120 5120 5120 5120 5120 5120 5120 5120 5120 5120 5120 5120 5120
				5120 5120 5120 5120 5120 5120 5120 5120 5120 5120 5120 5120 5120 5120 5120 5120 5120 5120 5120 5120 5120 5120 5120 5120 5120 5120 5120 5120 5120 5120 5120 5120
				5120 5120 5120 5120 5120 5120 5120 5120 5120 5120 5120 5120 5120 5120 5120 5120 5120 5120 5120 5120 5120 5120 5120 5120 5120 5120 5120 5120 5120 5120 5120 5120
				5120 5120 5120 5120 5120 5120 5120 5120 5120 5120 5120 5120 5120 5120 5120 5120 5120 5120 5120 5120 5120 5120 5120 5120 5120 5120 5120 5120 5120 5120 5120 5120
				5120 5120 5120 5120 5120 5120 5120 5120 5120 5120 5120 5120 5120 5120 5120 5120 5120 5120 5120 5120 5120 5120 5120 5120 5120 5120 5120 5120 5120 5120 5120 5120
				5120 5120 5120 5120 5120 5120 5120 5120 5120 5120 5120 5120 5120 5120 5120 5120 5120 5120 5120 5120 5120 5120 5120 5120 5120 5120 5120 5120 5120 5120 5120 5120
				5120 5120 5120 5120 5120 5120 5120 5120 5120 5120 5120 5120 5120 5120 5120 5120 5120 5120 5120 5120 5120 5120 5120 5120 5120 5120 5120 5120 5120 5120 5120 5120
				5120 5120 5120 5120 5120 5120 5120 5120 5120 5120 5120 5120 5120 5120 5120 5120 5120 5120 5120 5120 5120 5120 5120 5120 5120 5120 5120 5120 5120 5120 5120 5120
				5120 5120 5120 5120 5120 5120 5120 5120 5120 5120 5120 5120 5120 5120 5120 5120 5120 5120 5120 5120 5120 5120 5120 5120 5120 5120 5120 5120 5120 5120 5120 5120
				5120 5120 5120 5120 5120 5120 5120 5120 5120 5120 5120 5120 5120 5120 5120 5120 5120 5120 5120 5120 5120 5120 5120 5120 5120 5120 5120 5120 5120 5120 5120 5120
				5120 5120 5120 5120 5120 5120 5120 5120 5120 5120 5120 5120 5120 5120 5120 5120 5120 5120 5120 5120 5120 5120 5120 5120 5120 5120 5120 5120 5120 5120 5120 5120
				5120 5120 5120 5120 5120 5120 5120 5120 5120 5120 5120 5120 5120 5120 5120 5120 5120 5120 5120 5120 5120 5120 5120 5120 5120 5120 5120 5120 5120 5120 5120 5120
				5120 5120 5120 5120 5120 5120 5120 5120 5120 5120 5120 5120 5120 5120 5120 5120 5120 5120 5120 5120 5120 5120 5120 5120 5120 5120 5120 5120 5120 5120 5120 5120
				5120 5120 5120 5120 5120 5120 5120 5120 5120 5120 5120 5120 5120 5120 5120 5120 5120 5120 5120 5120 5120 5120 5120 5120 5120 5120 5120 5120 5120 5120 5120 5120
				5120 5120 5120 5120 5120 5120 5120 5120 5120 5120 5120 5120 5120 5120 5120 5120 5120 5120 5120 5120 5120 5120 5120 5120 5120 5120 5120 5120 5120 5120 5120 5120
				5120 5120 5120 5120 5120 5120 5120 5120 5120 5120 5120 5120 5120 5120 5120 5120 5120 5120 5120 5120 5120 5120 5120 5120 5120 5120 5120 5120 5120 5120 5120 5120
				5120 5120 5120 5120 5120 5120 5120 5120 5120 5120 5120 5120 5120 5120 5120 5120 5120 5120 5120 5120 5120 5120 5120 5120 5120 5120 5120 5120 5120 5120 5120 5120
				5120 5120 5120 5120 5120 5120 5120 5120 5120 5120 5120 5120 5120 5120 5120 5120 5120 5120 5120 5120 5120 5120 5120 5120 5120 5120 5120 5120 5120 5120 5120 5120
				5120 5120 5120 5120 5120 5120 5120 5120 5120 5120 5120 5120 5120 5120 5120 5120 5120 5120 5120 5120 5120 5120 5120 5120 5120 5120 5120 5120 5120 5120 5120 5120
				5120 5120 5120 5120 5120 5120 5120 5120 5120 5120 5120 5120 5120 5120 5120 5120 5120 5120 5120 5120 5120 5120 5120 5120 5120 5120 5120 5120 5120 5120 5120 5120
				5120 5120 5120 5120 5120 5120 5120 5120 5120 5120 5120 5120 5120 5120 5120 5120 5120 5120 5120 5120 5120 5120 5120 5120 5120 5120 5120 5120 5120 5120 5120 5120
				5120 5120 5120 5120 5120 5120 5120 5120 5120 5120 5120 5120 5120 5120 5120 5120 5120 5120 5120 5120 5120 5120 5120 5120 5120 5120 5120 5120 5120 5120 5120 5120
				5120 5120 5120 5120 5120 5120 5120 5120 5120 5120 5120 5120 5120 5120 5120 5120 5120 5120 5120 5120 5120 5120 5120 5120 5120 5120 5120 5120 5120 5120 5120 5120
				5120 5120 5120 5120 5120 5120 5120 5120 5120 5120 5120 5120 5120 5120 5120 5120 5120 5120 5120 5120 5120 5120 5120 5120 5120 5120 5120 5120 5120 5120 5120 5120
				5120 5120 5120 5120 5120 5120 5120 5120 5120 5120 5120 5120 5120 5120 5120 5120 5120 5120 5120 5120 5120 5120 5120 5120 5120 5120 5120 5120 5120 5120 5120 5120
				5120 5120 5120 5120 5120 5120 5120 5120 5120 5120 5120 5120 5120 5120 5120 5120 5120 5120 5120 5120 5120 5120 5120 5120 5120 5120 5120 5120 5120 5120 5120 5120
				5120 5120 5120>;

			PS_Config_Lmt_Open_Rawdata_N = <
				(-511) (-511) (-511) (-511) (-511) (-511) (-511) (-511) (-511) (-511) (-511) (-511) (-511) (-511) (-511) (-511) (-511) (-511) (-511) (-511) (-511) (-511) (-511) (-511) (-511) (-511) (-511) (-511) (-511) (-511) (-511) (-511)
				(-511) (-511) (-511) (-511) (-511) (-511) (-511) (-511) (-511) (-511) (-511) (-511) (-511) (-511) (-511) (-511) (-511) (-511) (-511) (-511) (-511) (-511) (-511) (-511) (-511) (-511) (-511) (-511) (-511) (-511) (-511) (-511)
				(-511) (-511) (-511) (-511) (-511) (-511) (-511) (-511) (-511) (-511) (-511) (-511) (-511) (-511) (-511) (-511) (-511) (-511) (-511) (-511) (-511) (-511) (-511) (-511) (-511) (-511) (-511) (-511) (-511) (-511) (-511) (-511)
				(-511) (-511) (-511) (-511) (-511) (-511) (-511) (-511) (-511) (-511) (-511) (-511) (-511) (-511) (-511) (-511) (-511) (-511) (-511) (-511) (-511) (-511) (-511) (-511) (-511) (-511) (-511) (-511) (-511) (-511) (-511) (-511)
				(-511) (-511) (-511) (-511) (-511) (-511) (-511) (-511) (-511) (-511) (-511) (-511) (-511) (-511) (-511) (-511) (-511) (-511) (-511) (-511) (-511) (-511) (-511) (-511) (-511) (-511) (-511) (-511) (-511) (-511) (-511) (-511)
				(-511) (-511) (-511) (-511) (-511) (-511) (-511) (-511) (-511) (-511) (-511) (-511) (-511) (-511) (-511) (-511) (-511) (-511) (-511) (-511) (-511) (-511) (-511) (-511) (-511) (-511) (-511) (-511) (-511) (-511) (-511) (-511)
				(-511) (-511) (-511) (-511) (-511) (-511) (-511) (-511) (-511) (-511) (-511) (-511) (-511) (-511) (-511) (-511) (-511) (-511) (-511) (-511) (-511) (-511) (-511) (-511) (-511) (-511) (-511) (-511) (-511) (-511) (-511) (-511)
				(-511) (-511) (-511) (-511) (-511) (-511) (-511) (-511) (-511) (-511) (-511) (-511) (-511) (-511) (-511) (-511) (-511) (-511) (-511) (-511) (-511) (-511) (-511) (-511) (-511) (-511) (-511) (-511) (-511) (-511) (-511) (-511)
				(-511) (-511) (-511) (-511) (-511) (-511) (-511) (-511) (-511) (-511) (-511) (-511) (-511) (-511) (-511) (-511) (-511) (-511) (-511) (-511) (-511) (-511) (-511) (-511) (-511) (-511) (-511) (-511) (-511) (-511) (-511) (-511)
				(-511) (-511) (-511) (-511) (-511) (-511) (-511) (-511) (-511) (-511) (-511) (-511) (-511) (-511) (-511) (-511) (-511) (-511) (-511) (-511) (-511) (-511) (-511) (-511) (-511) (-511) (-511) (-511) (-511) (-511) (-511) (-511)
				(-511) (-511) (-511) (-511) (-511) (-511) (-511) (-511) (-511) (-511) (-511) (-511) (-511) (-511) (-511) (-511) (-511) (-511) (-511) (-511) (-511) (-511) (-511) (-511) (-511) (-511) (-511) (-511) (-511) (-511) (-511) (-511)
				(-511) (-511) (-511) (-511) (-511) (-511) (-511) (-511) (-511) (-511) (-511) (-511) (-511) (-511) (-511) (-511) (-511) (-511) (-511) (-511) (-511) (-511) (-511) (-511) (-511) (-511) (-511) (-511) (-511) (-511) (-511) (-511)
				(-511) (-511) (-511) (-511) (-511) (-511) (-511) (-511) (-511) (-511) (-511) (-511) (-511) (-511) (-511) (-511) (-511) (-511) (-511) (-511) (-511) (-511) (-511) (-511) (-511) (-511) (-511) (-511) (-511) (-511) (-511) (-511)
				(-511) (-511) (-511) (-511) (-511) (-511) (-511) (-511) (-511) (-511) (-511) (-511) (-511) (-511) (-511) (-511) (-511) (-511) (-511) (-511) (-511) (-511) (-511) (-511) (-511) (-511) (-511) (-511) (-511) (-511) (-511) (-511)
				(-511) (-511) (-511) (-511) (-511) (-511) (-511) (-511) (-511) (-511) (-511) (-511) (-511) (-511) (-511) (-511) (-511) (-511) (-511) (-511) (-511) (-511) (-511) (-511) (-511) (-511) (-511) (-511) (-511) (-511) (-511) (-511)
				(-511) (-511) (-511) (-511) (-511) (-511) (-511) (-511) (-511) (-511) (-511) (-511) (-511) (-511) (-511) (-511) (-511) (-511) (-511) (-511) (-511) (-511) (-511) (-511) (-511) (-511) (-511) (-511) (-511) (-511) (-511) (-511)
				(-511) (-511) (-511) (-511) (-511) (-511) (-511) (-511) (-511) (-511) (-511) (-511) (-511) (-511) (-511) (-511) (-511) (-511) (-511) (-511) (-511) (-511) (-511) (-511) (-511) (-511) (-511) (-511) (-511) (-511) (-511) (-511)
				(-511) (-511) (-511) (-511) (-511) (-511) (-511) (-511) (-511) (-511) (-511) (-511) (-511) (-511) (-511) (-511) (-511) (-511) (-511) (-511) (-511) (-511) (-511) (-511) (-511) (-511) (-511) (-511) (-511) (-511) (-511) (-511)
				(-511) (-511) (-511) (-511) (-511) (-511) (-511) (-511) (-511) (-511) (-511) (-511) (-511) (-511) (-511) (-511) (-511) (-511) (-511) (-511) (-511) (-511) (-511) (-511) (-511) (-511) (-511) (-511) (-511) (-511) (-511) (-511)
				(-511) (-511) (-511) (-511) (-511) (-511) (-511) (-511) (-511) (-511) (-511) (-511) (-511) (-511) (-511) (-511) (-511) (-511) (-511) (-511) (-511) (-511) (-511) (-511) (-511) (-511) (-511) (-511) (-511) (-511) (-511) (-511)
				(-511) (-511) (-511) (-511) (-511) (-511) (-511) (-511) (-511) (-511) (-511) (-511) (-511) (-511) (-511) (-511) (-511) (-511) (-511) (-511) (-511) (-511) (-511) (-511) (-511) (-511) (-511) (-511) (-511) (-511) (-511) (-511)
				(-511) (-511) (-511) (-511) (-511) (-511) (-511) (-511) (-511) (-511) (-511) (-511) (-511) (-511) (-511) (-511) (-511) (-511) (-511) (-511) (-511) (-511) (-511) (-511) (-511) (-511) (-511) (-511) (-511) (-511) (-511) (-511)
				(-511) (-511) (-511) (-511) (-511) (-511) (-511) (-511) (-511) (-511) (-511) (-511) (-511) (-511) (-511) (-511) (-511) (-511) (-511) (-511) (-511) (-511) (-511) (-511) (-511) (-511) (-511) (-511) (-511) (-511) (-511) (-511)
				(-511) (-511) (-511) (-511) (-511) (-511) (-511) (-511) (-511) (-511) (-511) (-511) (-511) (-511) (-511) (-511) (-511) (-511) (-511) (-511) (-511) (-511) (-511) (-511) (-511) (-511) (-511) (-511) (-511) (-511) (-511) (-511)
				(-511) (-511) (-511) (-511) (-511) (-511) (-511) (-511) (-511) (-511) (-511) (-511) (-511) (-511) (-511) (-511) (-511) (-511) (-511) (-511) (-511) (-511) (-511) (-511) (-511) (-511) (-511) (-511) (-511) (-511) (-511) (-511)
				(-511) (-511) (-511) (-511) (-511) (-511) (-511) (-511) (-511) (-511) (-511) (-511) (-511) (-511) (-511) (-511) (-511) (-511) (-511) (-511) (-511) (-511) (-511) (-511) (-511) (-511) (-511) (-511) (-511) (-511) (-511) (-511)
				(-511) (-511) (-511) (-511) (-511) (-511) (-511) (-511) (-511) (-511) (-511) (-511) (-511) (-511) (-511) (-511) (-511) (-511) (-511) (-511) (-511) (-511) (-511) (-511) (-511) (-511) (-511) (-511) (-511) (-511) (-511) (-511)
				(-511) (-511) (-511) (-511) (-511) (-511) (-511) (-511) (-511) (-511) (-511) (-511) (-511) (-511) (-511) (-511) (-511) (-511) (-511) (-511) (-511) (-511) (-511) (-511) (-511) (-511) (-511) (-511) (-511) (-511) (-511) (-511)
				(-511) (-511) (-511) (-511) (-511) (-511) (-511) (-511) (-511) (-511) (-511) (-511) (-511) (-511) (-511) (-511) (-511) (-511) (-511) (-511) (-511) (-511) (-511) (-511) (-511) (-511) (-511) (-511) (-511) (-511) (-511) (-511)
				(-511) (-511) (-511) (-511) (-511) (-511) (-511) (-511) (-511) (-511) (-511) (-511) (-511) (-511) (-511) (-511) (-511) (-511) (-511) (-511) (-511) (-511) (-511) (-511) (-511) (-511) (-511) (-511) (-511) (-511) (-511) (-511)
				(-511) (-511) (-511) (-511) (-511) (-511) (-511) (-511) (-511) (-511) (-511) (-511) (-511) (-511) (-511) (-511) (-511) (-511) (-511) (-511) (-511) (-511) (-511) (-511) (-511) (-511) (-511) (-511) (-511) (-511) (-511) (-511)
				(-511) (-511) (-511) (-511) (-511) (-511) (-511) (-511) (-511) (-511) (-511) (-511) (-511) (-511) (-511) (-511) (-511) (-511) (-511) (-511) (-511) (-511) (-511) (-511) (-511) (-511) (-511) (-511) (-511) (-511) (-511) (-511)
				(-511) (-511) (-511) (-511) (-511) (-511) (-511) (-511) (-511) (-511) (-511) (-511) (-511) (-511) (-511) (-511) (-511) (-511) (-511) (-511) (-511) (-511) (-511) (-511) (-511) (-511) (-511) (-511) (-511) (-511) (-511) (-511)
				(-511) (-511) (-511) (-511) (-511) (-511) (-511) (-511) (-511) (-511) (-511) (-511) (-511) (-511) (-511) (-511) (-511) (-511) (-511) (-511) (-511) (-511) (-511) (-511) (-511) (-511) (-511) (-511) (-511) (-511) (-511) (-511)
				(-511) (-511) (-511) (-511) (-511) (-511) (-511) (-511) (-511) (-511) (-511) (-511) (-511) (-511) (-511) (-511) (-511) (-511) (-511) (-511) (-511) (-511) (-511) (-511) (-511) (-511) (-511) (-511) (-511) (-511) (-511) (-511)
				(-511) (-511) (-511) (-511) (-511) (-511) (-511) (-511) (-511) (-511) (-511) (-511) (-511) (-511) (-511) (-511) (-511) (-511) (-511) (-511) (-511) (-511) (-511) (-511) (-511) (-511) (-511) (-511) (-511) (-511) (-511) (-511)
				(-511) (-511) (-511) (-511) (-511) (-511) (-511) (-511) (-511) (-511) (-511) (-511) (-511) (-511) (-511) (-511) (-511) (-511) (-511) (-511) (-511) (-511) (-511) (-511) (-511) (-511) (-511) (-511) (-511) (-511) (-511) (-511)
				(-511) (-511) (-511) (-511) (-511) (-511) (-511) (-511) (-511) (-511) (-511) (-511) (-511) (-511) (-511) (-511) (-511) (-511) (-511) (-511) (-511) (-511) (-511) (-511) (-511) (-511) (-511) (-511) (-511) (-511) (-511) (-511)
				(-511) (-511) (-511) (-511) (-511) (-511) (-511) (-511) (-511) (-511) (-511) (-511) (-511) (-511) (-511) (-511) (-511) (-511) (-511) (-511) (-511) (-511) (-511) (-511) (-511) (-511) (-511) (-511) (-511) (-511) (-511) (-511)
				(-511) (-511) (-511) (-511) (-511) (-511) (-511) (-511) (-511) (-511) (-511) (-511) (-511) (-511) (-511) (-511) (-511) (-511) (-511) (-511) (-511) (-511) (-511) (-511) (-511) (-511) (-511) (-511) (-511) (-511) (-511) (-511)
				(-511) (-511) (-511) (-511) (-511) (-511) (-511) (-511) (-511) (-511) (-511) (-511) (-511) (-511) (-511) (-511) (-511) (-511) (-511) (-511) (-511) (-511) (-511) (-511) (-511) (-511) (-511) (-511) (-511) (-511) (-511) (-511)
				(-511) (-511) (-511) (-511) (-511) (-511) (-511) (-511) (-511) (-511) (-511) (-511) (-511) (-511) (-511) (-511) (-511) (-511) (-511) (-511) (-511) (-511) (-511) (-511) (-511) (-511) (-511) (-511) (-511) (-511) (-511) (-511)
				(-511) (-511) (-511) (-511) (-511) (-511) (-511) (-511) (-511) (-511) (-511) (-511) (-511) (-511) (-511) (-511) (-511) (-511) (-511) (-511) (-511) (-511) (-511) (-511) (-511) (-511) (-511) (-511) (-511) (-511) (-511) (-511)
				(-511) (-511) (-511) (-511) (-511) (-511) (-511) (-511) (-511) (-511) (-511) (-511) (-511) (-511) (-511) (-511) (-511) (-511) (-511) (-511) (-511) (-511) (-511) (-511) (-511) (-511) (-511) (-511) (-511) (-511) (-511) (-511)
				(-511) (-511) (-511) (-511) (-511) (-511) (-511) (-511) (-511) (-511) (-511) (-511) (-511) (-511) (-511) (-511) (-511) (-511) (-511) (-511) (-511) (-511) (-511) (-511) (-511) (-511) (-511) (-511) (-511) (-511) (-511) (-511)
				(-511) (-511) (-511) (-511) (-511) (-511) (-511) (-511) (-511) (-511) (-511) (-511) (-511) (-511) (-511) (-511) (-511) (-511) (-511) (-511) (-511) (-511) (-511) (-511) (-511) (-511) (-511) (-511) (-511) (-511) (-511) (-511)
				(-511) (-511) (-511) (-511) (-511) (-511) (-511) (-511) (-511) (-511) (-511) (-511) (-511) (-511) (-511) (-511) (-511) (-511) (-511) (-511) (-511) (-511) (-511) (-511) (-511) (-511) (-511) (-511) (-511) (-511) (-511) (-511)
				(-511) (-511) (-511) (-511) (-511) (-511) (-511) (-511) (-511) (-511) (-511) (-511) (-511) (-511) (-511) (-511) (-511) (-511) (-511) (-511) (-511) (-511) (-511) (-511) (-511) (-511) (-511) (-511) (-511) (-511) (-511) (-511)
				(-511) (-511) (-511) (-511) (-511) (-511) (-511) (-511) (-511) (-511) (-511) (-511) (-511) (-511) (-511) (-511) (-511) (-511) (-511) (-511) (-511) (-511) (-511) (-511) (-511) (-511) (-511) (-511) (-511) (-511) (-511) (-511)
				(-511) (-511) (-511) (-511) (-511) (-511) (-511) (-511) (-511) (-511) (-511) (-511) (-511) (-511) (-511) (-511) (-511) (-511) (-511) (-511) (-511) (-511) (-511) (-511) (-511) (-511) (-511) (-511) (-511) (-511) (-511) (-511)
				(-511) (-511) (-511)>;

			PS_Config_Lmt_FW_Rawdata_P = <
				3840 3840 3840 3840 3840 3840 3840 3840 3840 3840 3840 3840 3840 3840 3840 3840 3840 3840 3840 3840 3840 3840 3840 3840 3840 3840 3840 3840 3840 3840 3840 3840
				3840 3840 3840 3840 3840 3840 3840 3840 3840 3840 3840 3840 3840 3840 3840 3840 3840 3840 3840 3840 3840 3840 3840 3840 3840 3840 3840 3840 3840 3840 3840 3840
				3840 3840 3840 3840 3840 3840 3840 3840 3840 3840 3840 3840 3840 3840 3840 3840 3840 3840 3840 3840 3840 3840 3840 3840 3840 3840 3840 3840 3840 3840 3840 3840
				3840 3840 3840 3840 3840 3840 3840 3840 3840 3840 3840 3840 3840 3840 3840 3840 3840 3840 3840 3840 3840 3840 3840 3840 3840 3840 3840 3840 3840 3840 3840 3840
				3840 3840 3840 3840 3840 3840 3840 3840 3840 3840 3840 3840 3840 3840 3840 3840 3840 3840 3840 3840 3840 3840 3840 3840 3840 3840 3840 3840 3840 3840 3840 3840
				3840 3840 3840 3840 3840 3840 3840 3840 3840 3840 3840 3840 3840 3840 3840 3840 3840 3840 3840 3840 3840 3840 3840 3840 3840 3840 3840 3840 3840 3840 3840 3840
				3840 3840 3840 3840 3840 3840 3840 3840 3840 3840 3840 3840 3840 3840 3840 3840 3840 3840 3840 3840 3840 3840 3840 3840 3840 3840 3840 3840 3840 3840 3840 3840
				3840 3840 3840 3840 3840 3840 3840 3840 3840 3840 3840 3840 3840 3840 3840 3840 3840 3840 3840 3840 3840 3840 3840 3840 3840 3840 3840 3840 3840 3840 3840 3840
				3840 3840 3840 3840 3840 3840 3840 3840 3840 3840 3840 3840 3840 3840 3840 3840 3840 3840 3840 3840 3840 3840 3840 3840 3840 3840 3840 3840 3840 3840 3840 3840
				3840 3840 3840 3840 3840 3840 3840 3840 3840 3840 3840 3840 3840 3840 3840 3840 3840 3840 3840 3840 3840 3840 3840 3840 3840 3840 3840 3840 3840 3840 3840 3840
				3840 3840 3840 3840 3840 3840 3840 3840 3840 3840 3840 3840 3840 3840 3840 3840 3840 3840 3840 3840 3840 3840 3840 3840 3840 3840 3840 3840 3840 3840 3840 3840
				3840 3840 3840 3840 3840 3840 3840 3840 3840 3840 3840 3840 3840 3840 3840 3840 3840 3840 3840 3840 3840 3840 3840 3840 3840 3840 3840 3840 3840 3840 3840 3840
				3840 3840 3840 3840 3840 3840 3840 3840 3840 3840 3840 3840 3840 3840 3840 3840 3840 3840 3840 3840 3840 3840 3840 3840 3840 3840 3840 3840 3840 3840 3840 3840
				3840 3840 3840 3840 3840 3840 3840 3840 3840 3840 3840 3840 3840 3840 3840 3840 3840 3840 3840 3840 3840 3840 3840 3840 3840 3840 3840 3840 3840 3840 3840 3840
				3840 3840 3840 3840 3840 3840 3840 3840 3840 3840 3840 3840 3840 3840 3840 3840 3840 3840 3840 3840 3840 3840 3840 3840 3840 3840 3840 3840 3840 3840 3840 3840
				3840 3840 3840 3840 3840 3840 3840 3840 3840 3840 3840 3840 3840 3840 3840 3840 3840 3840 3840 3840 3840 3840 3840 3840 3840 3840 3840 3840 3840 3840 3840 3840
				3840 3840 3840 3840 3840 3840 3840 3840 3840 3840 3840 3840 3840 3840 3840 3840 3840 3840 3840 3840 3840 3840 3840 3840 3840 3840 3840 3840 3840 3840 3840 3840
				3840 3840 3840 3840 3840 3840 3840 3840 3840 3840 3840 3840 3840 3840 3840 3840 3840 3840 3840 3840 3840 3840 3840 3840 3840 3840 3840 3840 3840 3840 3840 3840
				3840 3840 3840 3840 3840 3840 3840 3840 3840 3840 3840 3840 3840 3840 3840 3840 3840 3840 3840 3840 3840 3840 3840 3840 3840 3840 3840 3840 3840 3840 3840 3840
				3840 3840 3840 3840 3840 3840 3840 3840 3840 3840 3840 3840 3840 3840 3840 3840 3840 3840 3840 3840 3840 3840 3840 3840 3840 3840 3840 3840 3840 3840 3840 3840
				3840 3840 3840 3840 3840 3840 3840 3840 3840 3840 3840 3840 3840 3840 3840 3840 3840 3840 3840 3840 3840 3840 3840 3840 3840 3840 3840 3840 3840 3840 3840 3840
				3840 3840 3840 3840 3840 3840 3840 3840 3840 3840 3840 3840 3840 3840 3840 3840 3840 3840 3840 3840 3840 3840 3840 3840 3840 3840 3840 3840 3840 3840 3840 3840
				3840 3840 3840 3840 3840 3840 3840 3840 3840 3840 3840 3840 3840 3840 3840 3840 3840 3840 3840 3840 3840 3840 3840 3840 3840 3840 3840 3840 3840 3840 3840 3840
				3840 3840 3840 3840 3840 3840 3840 3840 3840 3840 3840 3840 3840 3840 3840 3840 3840 3840 3840 3840 3840 3840 3840 3840 3840 3840 3840 3840 3840 3840 3840 3840
				3840 3840 3840 3840 3840 3840 3840 3840 3840 3840 3840 3840 3840 3840 3840 3840 3840 3840 3840 3840 3840 3840 3840 3840 3840 3840 3840 3840 3840 3840 3840 3840
				3840 3840 3840 3840 3840 3840 3840 3840 3840 3840 3840 3840 3840 3840 3840 3840 3840 3840 3840 3840 3840 3840 3840 3840 3840 3840 3840 3840 3840 3840 3840 3840
				3840 3840 3840 3840 3840 3840 3840 3840 3840 3840 3840 3840 3840 3840 3840 3840 3840 3840 3840 3840 3840 3840 3840 3840 3840 3840 3840 3840 3840 3840 3840 3840
				3840 3840 3840 3840 3840 3840 3840 3840 3840 3840 3840 3840 3840 3840 3840 3840 3840 3840 3840 3840 3840 3840 3840 3840 3840 3840 3840 3840 3840 3840 3840 3840
				3840 3840 3840 3840 3840 3840 3840 3840 3840 3840 3840 3840 3840 3840 3840 3840 3840 3840 3840 3840 3840 3840 3840 3840 3840 3840 3840 3840 3840 3840 3840 3840
				3840 3840 3840 3840 3840 3840 3840 3840 3840 3840 3840 3840 3840 3840 3840 3840 3840 3840 3840 3840 3840 3840 3840 3840 3840 3840 3840 3840 3840 3840 3840 3840
				3840 3840 3840 3840 3840 3840 3840 3840 3840 3840 3840 3840 3840 3840 3840 3840 3840 3840 3840 3840 3840 3840 3840 3840 3840 3840 3840 3840 3840 3840 3840 3840
				3840 3840 3840 3840 3840 3840 3840 3840 3840 3840 3840 3840 3840 3840 3840 3840 3840 3840 3840 3840 3840 3840 3840 3840 3840 3840 3840 3840 3840 3840 3840 3840
				3840 3840 3840 3840 3840 3840 3840 3840 3840 3840 3840 3840 3840 3840 3840 3840 3840 3840 3840 3840 3840 3840 3840 3840 3840 3840 3840 3840 3840 3840 3840 3840
				3840 3840 3840 3840 3840 3840 3840 3840 3840 3840 3840 3840 3840 3840 3840 3840 3840 3840 3840 3840 3840 3840 3840 3840 3840 3840 3840 3840 3840 3840 3840 3840
				3840 3840 3840 3840 3840 3840 3840 3840 3840 3840 3840 3840 3840 3840 3840 3840 3840 3840 3840 3840 3840 3840 3840 3840 3840 3840 3840 3840 3840 3840 3840 3840
				3840 3840 3840 3840 3840 3840 3840 3840 3840 3840 3840 3840 3840 3840 3840 3840 3840 3840 3840 3840 3840 3840 3840 3840 3840 3840 3840 3840 3840 3840 3840 3840
				3840 3840 3840 3840 3840 3840 3840 3840 3840 3840 3840 3840 3840 3840 3840 3840 3840 3840 3840 3840 3840 3840 3840 3840 3840 3840 3840 3840 3840 3840 3840 3840
				3840 3840 3840 3840 3840 3840 3840 3840 3840 3840 3840 3840 3840 3840 3840 3840 3840 3840 3840 3840 3840 3840 3840 3840 3840 3840 3840 3840 3840 3840 3840 3840
				3840 3840 3840 3840 3840 3840 3840 3840 3840 3840 3840 3840 3840 3840 3840 3840 3840 3840 3840 3840 3840 3840 3840 3840 3840 3840 3840 3840 3840 3840 3840 3840
				3840 3840 3840 3840 3840 3840 3840 3840 3840 3840 3840 3840 3840 3840 3840 3840 3840 3840 3840 3840 3840 3840 3840 3840 3840 3840 3840 3840 3840 3840 3840 3840
				3840 3840 3840 3840 3840 3840 3840 3840 3840 3840 3840 3840 3840 3840 3840 3840 3840 3840 3840 3840 3840 3840 3840 3840 3840 3840 3840 3840 3840 3840 3840 3840
				3840 3840 3840 3840 3840 3840 3840 3840 3840 3840 3840 3840 3840 3840 3840 3840 3840 3840 3840 3840 3840 3840 3840 3840 3840 3840 3840 3840 3840 3840 3840 3840
				3840 3840 3840 3840 3840 3840 3840 3840 3840 3840 3840 3840 3840 3840 3840 3840 3840 3840 3840 3840 3840 3840 3840 3840 3840 3840 3840 3840 3840 3840 3840 3840
				3840 3840 3840 3840 3840 3840 3840 3840 3840 3840 3840 3840 3840 3840 3840 3840 3840 3840 3840 3840 3840 3840 3840 3840 3840 3840 3840 3840 3840 3840 3840 3840
				3840 3840 3840 3840 3840 3840 3840 3840 3840 3840 3840 3840 3840 3840 3840 3840 3840 3840 3840 3840 3840 3840 3840 3840 3840 3840 3840 3840 3840 3840 3840 3840
				3840 3840 3840 3840 3840 3840 3840 3840 3840 3840 3840 3840 3840 3840 3840 3840 3840 3840 3840 3840 3840 3840 3840 3840 3840 3840 3840 3840 3840 3840 3840 3840
				3840 3840 3840 3840 3840 3840 3840 3840 3840 3840 3840 3840 3840 3840 3840 3840 3840 3840 3840 3840 3840 3840 3840 3840 3840 3840 3840 3840 3840 3840 3840 3840
				3840 3840 3840 3840 3840 3840 3840 3840 3840 3840 3840 3840 3840 3840 3840 3840 3840 3840 3840 3840 3840 3840 3840 3840 3840 3840 3840 3840 3840 3840 3840 3840
				3840 3840 3840 3840 3840 3840 3840 3840 3840 3840 3840 3840 3840 3840 3840 3840 3840 3840 3840 3840 3840 3840 3840 3840 3840 3840 3840 3840 3840 3840 3840 3840
				3840 3840 3840 3840 3840 3840 3840 3840 3840 3840 3840 3840 3840 3840 3840 3840 3840 3840 3840 3840 3840 3840 3840 3840 3840 3840 3840 3840 3840 3840 3840 3840
				3840 3840 3840>;

			PS_Config_Lmt_FW_Rawdata_N = <
				240 240 240 240 240 240 240 240 240 240 240 240 240 240 240 240 240 240 240 240 240 240 240 240 240 240 240 240 240 240 240 240
				240 240 240 240 240 240 240 240 240 240 240 240 240 240 240 240 240 240 240 240 240 240 240 240 240 240 240 240 240 240 240 240
				240 240 240 240 240 240 240 240 240 240 240 240 240 240 240 240 240 240 240 240 240 240 240 240 240 240 240 240 240 240 240 240
				240 240 240 240 240 240 240 240 240 240 240 240 240 240 240 240 240 240 240 240 240 240 240 240 240 240 240 240 240 240 240 240
				240 240 240 240 240 240 240 240 240 240 240 240 240 240 240 240 240 240 240 240 240 240 240 240 240 240 240 240 240 240 240 240
				240 240 240 240 240 240 240 240 240 240 240 240 240 240 240 240 240 240 240 240 240 240 240 240 240 240 240 240 240 240 240 240
				240 240 240 240 240 240 240 240 240 240 240 240 240 240 240 240 240 240 240 240 240 240 240 240 240 240 240 240 240 240 240 240
				240 240 240 240 240 240 240 240 240 240 240 240 240 240 240 240 240 240 240 240 240 240 240 240 240 240 240 240 240 240 240 240
				240 240 240 240 240 240 240 240 240 240 240 240 240 240 240 240 240 240 240 240 240 240 240 240 240 240 240 240 240 240 240 240
				240 240 240 240 240 240 240 240 240 240 240 240 240 240 240 240 240 240 240 240 240 240 240 240 240 240 240 240 240 240 240 240
				240 240 240 240 240 240 240 240 240 240 240 240 240 240 240 240 240 240 240 240 240 240 240 240 240 240 240 240 240 240 240 240
				240 240 240 240 240 240 240 240 240 240 240 240 240 240 240 240 240 240 240 240 240 240 240 240 240 240 240 240 240 240 240 240
				240 240 240 240 240 240 240 240 240 240 240 240 240 240 240 240 240 240 240 240 240 240 240 240 240 240 240 240 240 240 240 240
				240 240 240 240 240 240 240 240 240 240 240 240 240 240 240 240 240 240 240 240 240 240 240 240 240 240 240 240 240 240 240 240
				240 240 240 240 240 240 240 240 240 240 240 240 240 240 240 240 240 240 240 240 240 240 240 240 240 240 240 240 240 240 240 240
				240 240 240 240 240 240 240 240 240 240 240 240 240 240 240 240 240 240 240 240 240 240 240 240 240 240 240 240 240 240 240 240
				240 240 240 240 240 240 240 240 240 240 240 240 240 240 240 240 240 240 240 240 240 240 240 240 240 240 240 240 240 240 240 240
				240 240 240 240 240 240 240 240 240 240 240 240 240 240 240 240 240 240 240 240 240 240 240 240 240 240 240 240 240 240 240 240
				240 240 240 240 240 240 240 240 240 240 240 240 240 240 240 240 240 240 240 240 240 240 240 240 240 240 240 240 240 240 240 240
				240 240 240 240 240 240 240 240 240 240 240 240 240 240 240 240 240 240 240 240 240 240 240 240 240 240 240 240 240 240 240 240
				240 240 240 240 240 240 240 240 240 240 240 240 240 240 240 240 240 240 240 240 240 240 240 240 240 240 240 240 240 240 240 240
				240 240 240 240 240 240 240 240 240 240 240 240 240 240 240 240 240 240 240 240 240 240 240 240 240 240 240 240 240 240 240 240
				240 240 240 240 240 240 240 240 240 240 240 240 240 240 240 240 240 240 240 240 240 240 240 240 240 240 240 240 240 240 240 240
				240 240 240 240 240 240 240 240 240 240 240 240 240 240 240 240 240 240 240 240 240 240 240 240 240 240 240 240 240 240 240 240
				240 240 240 240 240 240 240 240 240 240 240 240 240 240 240 240 240 240 240 240 240 240 240 240 240 240 240 240 240 240 240 240
				240 240 240 240 240 240 240 240 240 240 240 240 240 240 240 240 240 240 240 240 240 240 240 240 240 240 240 240 240 240 240 240
				240 240 240 240 240 240 240 240 240 240 240 240 240 240 240 240 240 240 240 240 240 240 240 240 240 240 240 240 240 240 240 240
				240 240 240 240 240 240 240 240 240 240 240 240 240 240 240 240 240 240 240 240 240 240 240 240 240 240 240 240 240 240 240 240
				240 240 240 240 240 240 240 240 240 240 240 240 240 240 240 240 240 240 240 240 240 240 240 240 240 240 240 240 240 240 240 240
				240 240 240 240 240 240 240 240 240 240 240 240 240 240 240 240 240 240 240 240 240 240 240 240 240 240 240 240 240 240 240 240
				240 240 240 240 240 240 240 240 240 240 240 240 240 240 240 240 240 240 240 240 240 240 240 240 240 240 240 240 240 240 240 240
				240 240 240 240 240 240 240 240 240 240 240 240 240 240 240 240 240 240 240 240 240 240 240 240 240 240 240 240 240 240 240 240
				240 240 240 240 240 240 240 240 240 240 240 240 240 240 240 240 240 240 240 240 240 240 240 240 240 240 240 240 240 240 240 240
				240 240 240 240 240 240 240 240 240 240 240 240 240 240 240 240 240 240 240 240 240 240 240 240 240 240 240 240 240 240 240 240
				240 240 240 240 240 240 240 240 240 240 240 240 240 240 240 240 240 240 240 240 240 240 240 240 240 240 240 240 240 240 240 240
				240 240 240 240 240 240 240 240 240 240 240 240 240 240 240 240 240 240 240 240 240 240 240 240 240 240 240 240 240 240 240 240
				240 240 240 240 240 240 240 240 240 240 240 240 240 240 240 240 240 240 240 240 240 240 240 240 240 240 240 240 240 240 240 240
				240 240 240 240 240 240 240 240 240 240 240 240 240 240 240 240 240 240 240 240 240 240 240 240 240 240 240 240 240 240 240 240
				240 240 240 240 240 240 240 240 240 240 240 240 240 240 240 240 240 240 240 240 240 240 240 240 240 240 240 240 240 240 240 240
				240 240 240 240 240 240 240 240 240 240 240 240 240 240 240 240 240 240 240 240 240 240 240 240 240 240 240 240 240 240 240 240
				240 240 240 240 240 240 240 240 240 240 240 240 240 240 240 240 240 240 240 240 240 240 240 240 240 240 240 240 240 240 240 240
				240 240 240 240 240 240 240 240 240 240 240 240 240 240 240 240 240 240 240 240 240 240 240 240 240 240 240 240 240 240 240 240
				240 240 240 240 240 240 240 240 240 240 240 240 240 240 240 240 240 240 240 240 240 240 240 240 240 240 240 240 240 240 240 240
				240 240 240 240 240 240 240 240 240 240 240 240 240 240 240 240 240 240 240 240 240 240 240 240 240 240 240 240 240 240 240 240
				240 240 240 240 240 240 240 240 240 240 240 240 240 240 240 240 240 240 240 240 240 240 240 240 240 240 240 240 240 240 240 240
				240 240 240 240 240 240 240 240 240 240 240 240 240 240 240 240 240 240 240 240 240 240 240 240 240 240 240 240 240 240 240 240
				240 240 240 240 240 240 240 240 240 240 240 240 240 240 240 240 240 240 240 240 240 240 240 240 240 240 240 240 240 240 240 240
				240 240 240 240 240 240 240 240 240 240 240 240 240 240 240 240 240 240 240 240 240 240 240 240 240 240 240 240 240 240 240 240
				240 240 240 240 240 240 240 240 240 240 240 240 240 240 240 240 240 240 240 240 240 240 240 240 240 240 240 240 240 240 240 240
				240 240 240 240 240 240 240 240 240 240 240 240 240 240 240 240 240 240 240 240 240 240 240 240 240 240 240 240 240 240 240 240
				240 240 240>;

			PS_Config_Lmt_FW_CC_P = <
				314 314 314 314 314 314 314 314 314 314 314 314 314 314 314 314 314 314 314 314 314 314 314 314 314 314 314 314 314 314 314 314
				314 314 314 314 314 314 314 314 314 314 314 314 314 314 314 314 314 314 314 314 314 314 314 314 314 314 314 314 314 314 314 314
				314 314 314 314 314 314 314 314 314 314 314 314 314 314 314 314 314 314 314 314 314 314 314 314 314 314 314 314 314 314 314 314
				314 314 314 314 314 314 314 314 314 314 314 314 314 314 314 314 314 314 314 314 314 314 314 314 314 314 314 314 314 314 314 314
				314 314 314 314 314 314 314 314 314 314 314 314 314 314 314 314 314 314 314 314 314 314 314 314 314 314 314 314 314 314 314 314
				314 314 314 314 314 314 314 314 314 314 314 314 314 314 314 314 314 314 314 314 314 314 314 314 314 314 314 314 314 314 314 314
				314 314 314 314 314 314 314 314 314 314 314 314 314 314 314 314 314 314 314 314 314 314 314 314 314 314 314 314 314 314 314 314
				314 314 314 314 314 314 314 314 314 314 314 314 314 314 314 314 314 314 314 314 314 314 314 314 314 314 314 314 314 314 314 314
				314 314 314 314 314 314 314 314 314 314 314 314 314 314 314 314 314 314 314 314 314 314 314 314 314 314 314 314 314 314 314 314
				314 314 314 314 314 314 314 314 314 314 314 314 314 314 314 314 314 314 314 314 314 314 314 314 314 314 314 314 314 314 314 314
				314 314 314 314 314 314 314 314 314 314 314 314 314 314 314 314 314 314 314 314 314 314 314 314 314 314 314 314 314 314 314 314
				314 314 314 314 314 314 314 314 314 314 314 314 314 314 314 314 314 314 314 314 314 314 314 314 314 314 314 314 314 314 314 314
				314 314 314 314 314 314 314 314 314 314 314 314 314 314 314 314 314 314 314 314 314 314 314 314 314 314 314 314 314 314 314 314
				314 314 314 314 314 314 314 314 314 314 314 314 314 314 314 314 314 314 314 314 314 314 314 314 314 314 314 314 314 314 314 314
				314 314 314 314 314 314 314 314 314 314 314 314 314 314 314 314 314 314 314 314 314 314 314 314 314 314 314 314 314 314 314 314
				314 314 314 314 314 314 314 314 314 314 314 314 314 314 314 314 314 314 314 314 314 314 314 314 314 314 314 314 314 314 314 314
				314 314 314 314 314 314 314 314 314 314 314 314 314 314 314 314 314 314 314 314 314 314 314 314 314 314 314 314 314 314 314 314
				314 314 314 314 314 314 314 314 314 314 314 314 314 314 314 314 314 314 314 314 314 314 314 314 314 314 314 314 314 314 314 314
				314 314 314 314 314 314 314 314 314 314 314 314 314 314 314 314 314 314 314 314 314 314 314 314 314 314 314 314 314 314 314 314
				314 314 314 314 314 314 314 314 314 314 314 314 314 314 314 314 314 314 314 314 314 314 314 314 314 314 314 314 314 314 314 314
				314 314 314 314 314 314 314 314 314 314 314 314 314 314 314 314 314 314 314 314 314 314 314 314 314 314 314 314 314 314 314 314
				314 314 314 314 314 314 314 314 314 314 314 314 314 314 314 314 314 314 314 314 314 314 314 314 314 314 314 314 314 314 314 314
				314 314 314 314 314 314 314 314 314 314 314 314 314 314 314 314 314 314 314 314 314 314 314 314 314 314 314 314 314 314 314 314
				314 314 314 314 314 314 314 314 314 314 314 314 314 314 314 314 314 314 314 314 314 314 314 314 314 314 314 314 314 314 314 314
				314 314 314 314 314 314 314 314 314 314 314 314 314 314 314 314 314 314 314 314 314 314 314 314 314 314 314 314 314 314 314 314
				314 314 314 314 314 314 314 314 314 314 314 314 314 314 314 314 314 314 314 314 314 314 314 314 314 314 314 314 314 314 314 314
				314 314 314 314 314 314 314 314 314 314 314 314 314 314 314 314 314 314 314 314 314 314 314 314 314 314 314 314 314 314 314 314
				314 314 314 314 314 314 314 314 314 314 314 314 314 314 314 314 314 314 314 314 314 314 314 314 314 314 314 314 314 314 314 314
				314 314 314 314 314 314 314 314 314 314 314 314 314 314 314 314 314 314 314 314 314 314 314 314 314 314 314 314 314 314 314 314
				314 314 314 314 314 314 314 314 314 314 314 314 314 314 314 314 314 314 314 314 314 314 314 314 314 314 314 314 314 314 314 314
				314 314 314 314 314 314 314 314 314 314 314 314 314 314 314 314 314 314 314 314 314 314 314 314 314 314 314 314 314 314 314 314
				314 314 314 314 314 314 314 314 314 314 314 314 314 314 314 314 314 314 314 314 314 314 314 314 314 314 314 314 314 314 314 314
				314 314 314 314 314 314 314 314 314 314 314 314 314 314 314 314 314 314 314 314 314 314 314 314 314 314 314 314 314 314 314 314
				314 314 314 314 314 314 314 314 314 314 314 314 314 314 314 314 314 314 314 314 314 314 314 314 314 314 314 314 314 314 314 314
				314 314 314 314 314 314 314 314 314 314 314 314 314 314 314 314 314 314 314 314 314 314 314 314 314 314 314 314 314 314 314 314
				314 314 314 314 314 314 314 314 314 314 314 314 314 314 314 314 314 314 314 314 314 314 314 314 314 314 314 314 314 314 314 314
				314 314 314 314 314 314 314 314 314 314 314 314 314 314 314 314 314 314 314 314 314 314 314 314 314 314 314 314 314 314 314 314
				314 314 314 314 314 314 314 314 314 314 314 314 314 314 314 314 314 314 314 314 314 314 314 314 314 314 314 314 314 314 314 314
				314 314 314 314 314 314 314 314 314 314 314 314 314 314 314 314 314 314 314 314 314 314 314 314 314 314 314 314 314 314 314 314
				314 314 314 314 314 314 314 314 314 314 314 314 314 314 314 314 314 314 314 314 314 314 314 314 314 314 314 314 314 314 314 314
				314 314 314 314 314 314 314 314 314 314 314 314 314 314 314 314 314 314 314 314 314 314 314 314 314 314 314 314 314 314 314 314
				314 314 314 314 314 314 314 314 314 314 314 314 314 314 314 314 314 314 314 314 314 314 314 314 314 314 314 314 314 314 314 314
				314 314 314 314 314 314 314 314 314 314 314 314 314 314 314 314 314 314 314 314 314 314 314 314 314 314 314 314 314 314 314 314
				314 314 314 314 314 314 314 314 314 314 314 314 314 314 314 314 314 314 314 314 314 314 314 314 314 314 314 314 314 314 314 314
				314 314 314 314 314 314 314 314 314 314 314 314 314 314 314 314 314 314 314 314 314 314 314 314 314 314 314 314 314 314 314 314
				314 314 314 314 314 314 314 314 314 314 314 314 314 314 314 314 314 314 314 314 314 314 314 314 314 314 314 314 314 314 314 314
				314 314 314 314 314 314 314 314 314 314 314 314 314 314 314 314 314 314 314 314 314 314 314 314 314 314 314 314 314 314 314 314
				314 314 314 314 314 314 314 314 314 314 314 314 314 314 314 314 314 314 314 314 314 314 314 314 314 314 314 314 314 314 314 314
				314 314 314 314 314 314 314 314 314 314 314 314 314 314 314 314 314 314 314 314 314 314 314 314 314 314 314 314 314 314 314 314
				314 314 314 314 314 314 314 314 314 314 314 314 314 314 314 314 314 314 314 314 314 314 314 314 314 314 314 314 314 314 314 314
				314 314 314>;

			PS_Config_Lmt_FW_CC_N = <
				0 0 0 0 0 0 0 0 0 0 0 0 0 0 0 0 0 0 0 0 0 0 0 0 0 0 0 0 0 0 0 0
				0 0 0 0 0 0 0 0 0 0 0 0 0 0 0 0 0 0 0 0 0 0 0 0 0 0 0 0 0 0 0 0
				0 0 0 0 0 0 0 0 0 0 0 0 0 0 0 0 0 0 0 0 0 0 0 0 0 0 0 0 0 0 0 0
				0 0 0 0 0 0 0 0 0 0 0 0 0 0 0 0 0 0 0 0 0 0 0 0 0 0 0 0 0 0 0 0
				0 0 0 0 0 0 0 0 0 0 0 0 0 0 0 0 0 0 0 0 0 0 0 0 0 0 0 0 0 0 0 0
				0 0 0 0 0 0 0 0 0 0 0 0 0 0 0 0 0 0 0 0 0 0 0 0 0 0 0 0 0 0 0 0
				0 0 0 0 0 0 0 0 0 0 0 0 0 0 0 0 0 0 0 0 0 0 0 0 0 0 0 0 0 0 0 0
				0 0 0 0 0 0 0 0 0 0 0 0 0 0 0 0 0 0 0 0 0 0 0 0 0 0 0 0 0 0 0 0
				0 0 0 0 0 0 0 0 0 0 0 0 0 0 0 0 0 0 0 0 0 0 0 0 0 0 0 0 0 0 0 0
				0 0 0 0 0 0 0 0 0 0 0 0 0 0 0 0 0 0 0 0 0 0 0 0 0 0 0 0 0 0 0 0
				0 0 0 0 0 0 0 0 0 0 0 0 0 0 0 0 0 0 0 0 0 0 0 0 0 0 0 0 0 0 0 0
				0 0 0 0 0 0 0 0 0 0 0 0 0 0 0 0 0 0 0 0 0 0 0 0 0 0 0 0 0 0 0 0
				0 0 0 0 0 0 0 0 0 0 0 0 0 0 0 0 0 0 0 0 0 0 0 0 0 0 0 0 0 0 0 0
				0 0 0 0 0 0 0 0 0 0 0 0 0 0 0 0 0 0 0 0 0 0 0 0 0 0 0 0 0 0 0 0
				0 0 0 0 0 0 0 0 0 0 0 0 0 0 0 0 0 0 0 0 0 0 0 0 0 0 0 0 0 0 0 0
				0 0 0 0 0 0 0 0 0 0 0 0 0 0 0 0 0 0 0 0 0 0 0 0 0 0 0 0 0 0 0 0
				0 0 0 0 0 0 0 0 0 0 0 0 0 0 0 0 0 0 0 0 0 0 0 0 0 0 0 0 0 0 0 0
				0 0 0 0 0 0 0 0 0 0 0 0 0 0 0 0 0 0 0 0 0 0 0 0 0 0 0 0 0 0 0 0
				0 0 0 0 0 0 0 0 0 0 0 0 0 0 0 0 0 0 0 0 0 0 0 0 0 0 0 0 0 0 0 0
				0 0 0 0 0 0 0 0 0 0 0 0 0 0 0 0 0 0 0 0 0 0 0 0 0 0 0 0 0 0 0 0
				0 0 0 0 0 0 0 0 0 0 0 0 0 0 0 0 0 0 0 0 0 0 0 0 0 0 0 0 0 0 0 0
				0 0 0 0 0 0 0 0 0 0 0 0 0 0 0 0 0 0 0 0 0 0 0 0 0 0 0 0 0 0 0 0
				0 0 0 0 0 0 0 0 0 0 0 0 0 0 0 0 0 0 0 0 0 0 0 0 0 0 0 0 0 0 0 0
				0 0 0 0 0 0 0 0 0 0 0 0 0 0 0 0 0 0 0 0 0 0 0 0 0 0 0 0 0 0 0 0
				0 0 0 0 0 0 0 0 0 0 0 0 0 0 0 0 0 0 0 0 0 0 0 0 0 0 0 0 0 0 0 0
				0 0 0 0 0 0 0 0 0 0 0 0 0 0 0 0 0 0 0 0 0 0 0 0 0 0 0 0 0 0 0 0
				0 0 0 0 0 0 0 0 0 0 0 0 0 0 0 0 0 0 0 0 0 0 0 0 0 0 0 0 0 0 0 0
				0 0 0 0 0 0 0 0 0 0 0 0 0 0 0 0 0 0 0 0 0 0 0 0 0 0 0 0 0 0 0 0
				0 0 0 0 0 0 0 0 0 0 0 0 0 0 0 0 0 0 0 0 0 0 0 0 0 0 0 0 0 0 0 0
				0 0 0 0 0 0 0 0 0 0 0 0 0 0 0 0 0 0 0 0 0 0 0 0 0 0 0 0 0 0 0 0
				0 0 0 0 0 0 0 0 0 0 0 0 0 0 0 0 0 0 0 0 0 0 0 0 0 0 0 0 0 0 0 0
				0 0 0 0 0 0 0 0 0 0 0 0 0 0 0 0 0 0 0 0 0 0 0 0 0 0 0 0 0 0 0 0
				0 0 0 0 0 0 0 0 0 0 0 0 0 0 0 0 0 0 0 0 0 0 0 0 0 0 0 0 0 0 0 0
				0 0 0 0 0 0 0 0 0 0 0 0 0 0 0 0 0 0 0 0 0 0 0 0 0 0 0 0 0 0 0 0
				0 0 0 0 0 0 0 0 0 0 0 0 0 0 0 0 0 0 0 0 0 0 0 0 0 0 0 0 0 0 0 0
				0 0 0 0 0 0 0 0 0 0 0 0 0 0 0 0 0 0 0 0 0 0 0 0 0 0 0 0 0 0 0 0
				0 0 0 0 0 0 0 0 0 0 0 0 0 0 0 0 0 0 0 0 0 0 0 0 0 0 0 0 0 0 0 0
				0 0 0 0 0 0 0 0 0 0 0 0 0 0 0 0 0 0 0 0 0 0 0 0 0 0 0 0 0 0 0 0
				0 0 0 0 0 0 0 0 0 0 0 0 0 0 0 0 0 0 0 0 0 0 0 0 0 0 0 0 0 0 0 0
				0 0 0 0 0 0 0 0 0 0 0 0 0 0 0 0 0 0 0 0 0 0 0 0 0 0 0 0 0 0 0 0
				0 0 0 0 0 0 0 0 0 0 0 0 0 0 0 0 0 0 0 0 0 0 0 0 0 0 0 0 0 0 0 0
				0 0 0 0 0 0 0 0 0 0 0 0 0 0 0 0 0 0 0 0 0 0 0 0 0 0 0 0 0 0 0 0
				0 0 0 0 0 0 0 0 0 0 0 0 0 0 0 0 0 0 0 0 0 0 0 0 0 0 0 0 0 0 0 0
				0 0 0 0 0 0 0 0 0 0 0 0 0 0 0 0 0 0 0 0 0 0 0 0 0 0 0 0 0 0 0 0
				0 0 0 0 0 0 0 0 0 0 0 0 0 0 0 0 0 0 0 0 0 0 0 0 0 0 0 0 0 0 0 0
				0 0 0 0 0 0 0 0 0 0 0 0 0 0 0 0 0 0 0 0 0 0 0 0 0 0 0 0 0 0 0 0
				0 0 0 0 0 0 0 0 0 0 0 0 0 0 0 0 0 0 0 0 0 0 0 0 0 0 0 0 0 0 0 0
				0 0 0 0 0 0 0 0 0 0 0 0 0 0 0 0 0 0 0 0 0 0 0 0 0 0 0 0 0 0 0 0
				0 0 0 0 0 0 0 0 0 0 0 0 0 0 0 0 0 0 0 0 0 0 0 0 0 0 0 0 0 0 0 0
				0 0 0 0 0 0 0 0 0 0 0 0 0 0 0 0 0 0 0 0 0 0 0 0 0 0 0 0 0 0 0 0
				0 0 0>;

			PS_Config_Lmt_FW_Diff_P = <
				75 75 75 75 75 75 75 75 75 75 75 75 75 75 75 75 75 75 75 75 75 75 75 75 75 75 75 75 75 75 75 75
				75 75 75 75 75 75 75 75 75 75 75 75 75 75 75 75 75 75 75 75 75 75 75 75 75 75 75 75 75 75 75 75
				75 75 75 75 75 75 75 75 75 75 75 75 75 75 75 75 75 75 75 75 75 75 75 75 75 75 75 75 75 75 75 75
				75 75 75 75 75 75 75 75 75 75 75 75 75 75 75 75 75 75 75 75 75 75 75 75 75 75 75 75 75 75 75 75
				75 75 75 75 75 75 75 75 75 75 75 75 75 75 75 75 75 75 75 75 75 75 75 75 75 75 75 75 75 75 75 75
				75 75 75 75 75 75 75 75 75 75 75 75 75 75 75 75 75 75 75 75 75 75 75 75 75 75 75 75 75 75 75 75
				75 75 75 75 75 75 75 75 75 75 75 75 75 75 75 75 75 75 75 75 75 75 75 75 75 75 75 75 75 75 75 75
				75 75 75 75 75 75 75 75 75 75 75 75 75 75 75 75 75 75 75 75 75 75 75 75 75 75 75 75 75 75 75 75
				75 75 75 75 75 75 75 75 75 75 75 75 75 75 75 75 75 75 75 75 75 75 75 75 75 75 75 75 75 75 75 75
				75 75 75 75 75 75 75 75 75 75 75 75 75 75 75 75 75 75 75 75 75 75 75 75 75 75 75 75 75 75 75 75
				75 75 75 75 75 75 75 75 75 75 75 75 75 75 75 75 75 75 75 75 75 75 75 75 75 75 75 75 75 75 75 75
				75 75 75 75 75 75 75 75 75 75 75 75 75 75 75 75 75 75 75 75 75 75 75 75 75 75 75 75 75 75 75 75
				75 75 75 75 75 75 75 75 75 75 75 75 75 75 75 75 75 75 75 75 75 75 75 75 75 75 75 75 75 75 75 75
				75 75 75 75 75 75 75 75 75 75 75 75 75 75 75 75 75 75 75 75 75 75 75 75 75 75 75 75 75 75 75 75
				75 75 75 75 75 75 75 75 75 75 75 75 75 75 75 75 75 75 75 75 75 75 75 75 75 75 75 75 75 75 75 75
				75 75 75 75 75 75 75 75 75 75 75 75 75 75 75 75 75 75 75 75 75 75 75 75 75 75 75 75 75 75 75 75
				75 75 75 75 75 75 75 75 75 75 75 75 75 75 75 75 75 75 75 75 75 75 75 75 75 75 75 75 75 75 75 75
				75 75 75 75 75 75 75 75 75 75 75 75 75 75 75 75 75 75 75 75 75 75 75 75 75 75 75 75 75 75 75 75
				75 75 75 75 75 75 75 75 75 75 75 75 75 75 75 75 75 75 75 75 75 75 75 75 75 75 75 75 75 75 75 75
				75 75 75 75 75 75 75 75 75 75 75 75 75 75 75 75 75 75 75 75 75 75 75 75 75 75 75 75 75 75 75 75
				75 75 75 75 75 75 75 75 75 75 75 75 75 75 75 75 75 75 75 75 75 75 75 75 75 75 75 75 75 75 75 75
				75 75 75 75 75 75 75 75 75 75 75 75 75 75 75 75 75 75 75 75 75 75 75 75 75 75 75 75 75 75 75 75
				75 75 75 75 75 75 75 75 75 75 75 75 75 75 75 75 75 75 75 75 75 75 75 75 75 75 75 75 75 75 75 75
				75 75 75 75 75 75 75 75 75 75 75 75 75 75 75 75 75 75 75 75 75 75 75 75 75 75 75 75 75 75 75 75
				75 75 75 75 75 75 75 75 75 75 75 75 75 75 75 75 75 75 75 75 75 75 75 75 75 75 75 75 75 75 75 75
				75 75 75 75 75 75 75 75 75 75 75 75 75 75 75 75 75 75 75 75 75 75 75 75 75 75 75 75 75 75 75 75
				75 75 75 75 75 75 75 75 75 75 75 75 75 75 75 75 75 75 75 75 75 75 75 75 75 75 75 75 75 75 75 75
				75 75 75 75 75 75 75 75 75 75 75 75 75 75 75 75 75 75 75 75 75 75 75 75 75 75 75 75 75 75 75 75
				75 75 75 75 75 75 75 75 75 75 75 75 75 75 75 75 75 75 75 75 75 75 75 75 75 75 75 75 75 75 75 75
				75 75 75 75 75 75 75 75 75 75 75 75 75 75 75 75 75 75 75 75 75 75 75 75 75 75 75 75 75 75 75 75
				75 75 75 75 75 75 75 75 75 75 75 75 75 75 75 75 75 75 75 75 75 75 75 75 75 75 75 75 75 75 75 75
				75 75 75 75 75 75 75 75 75 75 75 75 75 75 75 75 75 75 75 75 75 75 75 75 75 75 75 75 75 75 75 75
				75 75 75 75 75 75 75 75 75 75 75 75 75 75 75 75 75 75 75 75 75 75 75 75 75 75 75 75 75 75 75 75
				75 75 75 75 75 75 75 75 75 75 75 75 75 75 75 75 75 75 75 75 75 75 75 75 75 75 75 75 75 75 75 75
				75 75 75 75 75 75 75 75 75 75 75 75 75 75 75 75 75 75 75 75 75 75 75 75 75 75 75 75 75 75 75 75
				75 75 75 75 75 75 75 75 75 75 75 75 75 75 75 75 75 75 75 75 75 75 75 75 75 75 75 75 75 75 75 75
				75 75 75 75 75 75 75 75 75 75 75 75 75 75 75 75 75 75 75 75 75 75 75 75 75 75 75 75 75 75 75 75
				75 75 75 75 75 75 75 75 75 75 75 75 75 75 75 75 75 75 75 75 75 75 75 75 75 75 75 75 75 75 75 75
				75 75 75 75 75 75 75 75 75 75 75 75 75 75 75 75 75 75 75 75 75 75 75 75 75 75 75 75 75 75 75 75
				75 75 75 75 75 75 75 75 75 75 75 75 75 75 75 75 75 75 75 75 75 75 75 75 75 75 75 75 75 75 75 75
				75 75 75 75 75 75 75 75 75 75 75 75 75 75 75 75 75 75 75 75 75 75 75 75 75 75 75 75 75 75 75 75
				75 75 75 75 75 75 75 75 75 75 75 75 75 75 75 75 75 75 75 75 75 75 75 75 75 75 75 75 75 75 75 75
				75 75 75 75 75 75 75 75 75 75 75 75 75 75 75 75 75 75 75 75 75 75 75 75 75 75 75 75 75 75 75 75
				75 75 75 75 75 75 75 75 75 75 75 75 75 75 75 75 75 75 75 75 75 75 75 75 75 75 75 75 75 75 75 75
				75 75 75 75 75 75 75 75 75 75 75 75 75 75 75 75 75 75 75 75 75 75 75 75 75 75 75 75 75 75 75 75
				75 75 75 75 75 75 75 75 75 75 75 75 75 75 75 75 75 75 75 75 75 75 75 75 75 75 75 75 75 75 75 75
				75 75 75 75 75 75 75 75 75 75 75 75 75 75 75 75 75 75 75 75 75 75 75 75 75 75 75 75 75 75 75 75
				75 75 75 75 75 75 75 75 75 75 75 75 75 75 75 75 75 75 75 75 75 75 75 75 75 75 75 75 75 75 75 75
				75 75 75 75 75 75 75 75 75 75 75 75 75 75 75 75 75 75 75 75 75 75 75 75 75 75 75 75 75 75 75 75
				75 75 75 75 75 75 75 75 75 75 75 75 75 75 75 75 75 75 75 75 75 75 75 75 75 75 75 75 75 75 75 75
				75 75 75>;

			PS_Config_Lmt_FW_Diff_N = <
				(-75) (-75) (-75) (-75) (-75) (-75) (-75) (-75) (-75) (-75) (-75) (-75) (-75) (-75) (-75) (-75) (-75) (-75) (-75) (-75) (-75) (-75) (-75) (-75) (-75) (-75) (-75) (-75) (-75) (-75) (-75) (-75)
				(-75) (-75) (-75) (-75) (-75) (-75) (-75) (-75) (-75) (-75) (-75) (-75) (-75) (-75) (-75) (-75) (-75) (-75) (-75) (-75) (-75) (-75) (-75) (-75) (-75) (-75) (-75) (-75) (-75) (-75) (-75) (-75)
				(-75) (-75) (-75) (-75) (-75) (-75) (-75) (-75) (-75) (-75) (-75) (-75) (-75) (-75) (-75) (-75) (-75) (-75) (-75) (-75) (-75) (-75) (-75) (-75) (-75) (-75) (-75) (-75) (-75) (-75) (-75) (-75)
				(-75) (-75) (-75) (-75) (-75) (-75) (-75) (-75) (-75) (-75) (-75) (-75) (-75) (-75) (-75) (-75) (-75) (-75) (-75) (-75) (-75) (-75) (-75) (-75) (-75) (-75) (-75) (-75) (-75) (-75) (-75) (-75)
				(-75) (-75) (-75) (-75) (-75) (-75) (-75) (-75) (-75) (-75) (-75) (-75) (-75) (-75) (-75) (-75) (-75) (-75) (-75) (-75) (-75) (-75) (-75) (-75) (-75) (-75) (-75) (-75) (-75) (-75) (-75) (-75)
				(-75) (-75) (-75) (-75) (-75) (-75) (-75) (-75) (-75) (-75) (-75) (-75) (-75) (-75) (-75) (-75) (-75) (-75) (-75) (-75) (-75) (-75) (-75) (-75) (-75) (-75) (-75) (-75) (-75) (-75) (-75) (-75)
				(-75) (-75) (-75) (-75) (-75) (-75) (-75) (-75) (-75) (-75) (-75) (-75) (-75) (-75) (-75) (-75) (-75) (-75) (-75) (-75) (-75) (-75) (-75) (-75) (-75) (-75) (-75) (-75) (-75) (-75) (-75) (-75)
				(-75) (-75) (-75) (-75) (-75) (-75) (-75) (-75) (-75) (-75) (-75) (-75) (-75) (-75) (-75) (-75) (-75) (-75) (-75) (-75) (-75) (-75) (-75) (-75) (-75) (-75) (-75) (-75) (-75) (-75) (-75) (-75)
				(-75) (-75) (-75) (-75) (-75) (-75) (-75) (-75) (-75) (-75) (-75) (-75) (-75) (-75) (-75) (-75) (-75) (-75) (-75) (-75) (-75) (-75) (-75) (-75) (-75) (-75) (-75) (-75) (-75) (-75) (-75) (-75)
				(-75) (-75) (-75) (-75) (-75) (-75) (-75) (-75) (-75) (-75) (-75) (-75) (-75) (-75) (-75) (-75) (-75) (-75) (-75) (-75) (-75) (-75) (-75) (-75) (-75) (-75) (-75) (-75) (-75) (-75) (-75) (-75)
				(-75) (-75) (-75) (-75) (-75) (-75) (-75) (-75) (-75) (-75) (-75) (-75) (-75) (-75) (-75) (-75) (-75) (-75) (-75) (-75) (-75) (-75) (-75) (-75) (-75) (-75) (-75) (-75) (-75) (-75) (-75) (-75)
				(-75) (-75) (-75) (-75) (-75) (-75) (-75) (-75) (-75) (-75) (-75) (-75) (-75) (-75) (-75) (-75) (-75) (-75) (-75) (-75) (-75) (-75) (-75) (-75) (-75) (-75) (-75) (-75) (-75) (-75) (-75) (-75)
				(-75) (-75) (-75) (-75) (-75) (-75) (-75) (-75) (-75) (-75) (-75) (-75) (-75) (-75) (-75) (-75) (-75) (-75) (-75) (-75) (-75) (-75) (-75) (-75) (-75) (-75) (-75) (-75) (-75) (-75) (-75) (-75)
				(-75) (-75) (-75) (-75) (-75) (-75) (-75) (-75) (-75) (-75) (-75) (-75) (-75) (-75) (-75) (-75) (-75) (-75) (-75) (-75) (-75) (-75) (-75) (-75) (-75) (-75) (-75) (-75) (-75) (-75) (-75) (-75)
				(-75) (-75) (-75) (-75) (-75) (-75) (-75) (-75) (-75) (-75) (-75) (-75) (-75) (-75) (-75) (-75) (-75) (-75) (-75) (-75) (-75) (-75) (-75) (-75) (-75) (-75) (-75) (-75) (-75) (-75) (-75) (-75)
				(-75) (-75) (-75) (-75) (-75) (-75) (-75) (-75) (-75) (-75) (-75) (-75) (-75) (-75) (-75) (-75) (-75) (-75) (-75) (-75) (-75) (-75) (-75) (-75) (-75) (-75) (-75) (-75) (-75) (-75) (-75) (-75)
				(-75) (-75) (-75) (-75) (-75) (-75) (-75) (-75) (-75) (-75) (-75) (-75) (-75) (-75) (-75) (-75) (-75) (-75) (-75) (-75) (-75) (-75) (-75) (-75) (-75) (-75) (-75) (-75) (-75) (-75) (-75) (-75)
				(-75) (-75) (-75) (-75) (-75) (-75) (-75) (-75) (-75) (-75) (-75) (-75) (-75) (-75) (-75) (-75) (-75) (-75) (-75) (-75) (-75) (-75) (-75) (-75) (-75) (-75) (-75) (-75) (-75) (-75) (-75) (-75)
				(-75) (-75) (-75) (-75) (-75) (-75) (-75) (-75) (-75) (-75) (-75) (-75) (-75) (-75) (-75) (-75) (-75) (-75) (-75) (-75) (-75) (-75) (-75) (-75) (-75) (-75) (-75) (-75) (-75) (-75) (-75) (-75)
				(-75) (-75) (-75) (-75) (-75) (-75) (-75) (-75) (-75) (-75) (-75) (-75) (-75) (-75) (-75) (-75) (-75) (-75) (-75) (-75) (-75) (-75) (-75) (-75) (-75) (-75) (-75) (-75) (-75) (-75) (-75) (-75)
				(-75) (-75) (-75) (-75) (-75) (-75) (-75) (-75) (-75) (-75) (-75) (-75) (-75) (-75) (-75) (-75) (-75) (-75) (-75) (-75) (-75) (-75) (-75) (-75) (-75) (-75) (-75) (-75) (-75) (-75) (-75) (-75)
				(-75) (-75) (-75) (-75) (-75) (-75) (-75) (-75) (-75) (-75) (-75) (-75) (-75) (-75) (-75) (-75) (-75) (-75) (-75) (-75) (-75) (-75) (-75) (-75) (-75) (-75) (-75) (-75) (-75) (-75) (-75) (-75)
				(-75) (-75) (-75) (-75) (-75) (-75) (-75) (-75) (-75) (-75) (-75) (-75) (-75) (-75) (-75) (-75) (-75) (-75) (-75) (-75) (-75) (-75) (-75) (-75) (-75) (-75) (-75) (-75) (-75) (-75) (-75) (-75)
				(-75) (-75) (-75) (-75) (-75) (-75) (-75) (-75) (-75) (-75) (-75) (-75) (-75) (-75) (-75) (-75) (-75) (-75) (-75) (-75) (-75) (-75) (-75) (-75) (-75) (-75) (-75) (-75) (-75) (-75) (-75) (-75)
				(-75) (-75) (-75) (-75) (-75) (-75) (-75) (-75) (-75) (-75) (-75) (-75) (-75) (-75) (-75) (-75) (-75) (-75) (-75) (-75) (-75) (-75) (-75) (-75) (-75) (-75) (-75) (-75) (-75) (-75) (-75) (-75)
				(-75) (-75) (-75) (-75) (-75) (-75) (-75) (-75) (-75) (-75) (-75) (-75) (-75) (-75) (-75) (-75) (-75) (-75) (-75) (-75) (-75) (-75) (-75) (-75) (-75) (-75) (-75) (-75) (-75) (-75) (-75) (-75)
				(-75) (-75) (-75) (-75) (-75) (-75) (-75) (-75) (-75) (-75) (-75) (-75) (-75) (-75) (-75) (-75) (-75) (-75) (-75) (-75) (-75) (-75) (-75) (-75) (-75) (-75) (-75) (-75) (-75) (-75) (-75) (-75)
				(-75) (-75) (-75) (-75) (-75) (-75) (-75) (-75) (-75) (-75) (-75) (-75) (-75) (-75) (-75) (-75) (-75) (-75) (-75) (-75) (-75) (-75) (-75) (-75) (-75) (-75) (-75) (-75) (-75) (-75) (-75) (-75)
				(-75) (-75) (-75) (-75) (-75) (-75) (-75) (-75) (-75) (-75) (-75) (-75) (-75) (-75) (-75) (-75) (-75) (-75) (-75) (-75) (-75) (-75) (-75) (-75) (-75) (-75) (-75) (-75) (-75) (-75) (-75) (-75)
				(-75) (-75) (-75) (-75) (-75) (-75) (-75) (-75) (-75) (-75) (-75) (-75) (-75) (-75) (-75) (-75) (-75) (-75) (-75) (-75) (-75) (-75) (-75) (-75) (-75) (-75) (-75) (-75) (-75) (-75) (-75) (-75)
				(-75) (-75) (-75) (-75) (-75) (-75) (-75) (-75) (-75) (-75) (-75) (-75) (-75) (-75) (-75) (-75) (-75) (-75) (-75) (-75) (-75) (-75) (-75) (-75) (-75) (-75) (-75) (-75) (-75) (-75) (-75) (-75)
				(-75) (-75) (-75) (-75) (-75) (-75) (-75) (-75) (-75) (-75) (-75) (-75) (-75) (-75) (-75) (-75) (-75) (-75) (-75) (-75) (-75) (-75) (-75) (-75) (-75) (-75) (-75) (-75) (-75) (-75) (-75) (-75)
				(-75) (-75) (-75) (-75) (-75) (-75) (-75) (-75) (-75) (-75) (-75) (-75) (-75) (-75) (-75) (-75) (-75) (-75) (-75) (-75) (-75) (-75) (-75) (-75) (-75) (-75) (-75) (-75) (-75) (-75) (-75) (-75)
				(-75) (-75) (-75) (-75) (-75) (-75) (-75) (-75) (-75) (-75) (-75) (-75) (-75) (-75) (-75) (-75) (-75) (-75) (-75) (-75) (-75) (-75) (-75) (-75) (-75) (-75) (-75) (-75) (-75) (-75) (-75) (-75)
				(-75) (-75) (-75) (-75) (-75) (-75) (-75) (-75) (-75) (-75) (-75) (-75) (-75) (-75) (-75) (-75) (-75) (-75) (-75) (-75) (-75) (-75) (-75) (-75) (-75) (-75) (-75) (-75) (-75) (-75) (-75) (-75)
				(-75) (-75) (-75) (-75) (-75) (-75) (-75) (-75) (-75) (-75) (-75) (-75) (-75) (-75) (-75) (-75) (-75) (-75) (-75) (-75) (-75) (-75) (-75) (-75) (-75) (-75) (-75) (-75) (-75) (-75) (-75) (-75)
				(-75) (-75) (-75) (-75) (-75) (-75) (-75) (-75) (-75) (-75) (-75) (-75) (-75) (-75) (-75) (-75) (-75) (-75) (-75) (-75) (-75) (-75) (-75) (-75) (-75) (-75) (-75) (-75) (-75) (-75) (-75) (-75)
				(-75) (-75) (-75) (-75) (-75) (-75) (-75) (-75) (-75) (-75) (-75) (-75) (-75) (-75) (-75) (-75) (-75) (-75) (-75) (-75) (-75) (-75) (-75) (-75) (-75) (-75) (-75) (-75) (-75) (-75) (-75) (-75)
				(-75) (-75) (-75) (-75) (-75) (-75) (-75) (-75) (-75) (-75) (-75) (-75) (-75) (-75) (-75) (-75) (-75) (-75) (-75) (-75) (-75) (-75) (-75) (-75) (-75) (-75) (-75) (-75) (-75) (-75) (-75) (-75)
				(-75) (-75) (-75) (-75) (-75) (-75) (-75) (-75) (-75) (-75) (-75) (-75) (-75) (-75) (-75) (-75) (-75) (-75) (-75) (-75) (-75) (-75) (-75) (-75) (-75) (-75) (-75) (-75) (-75) (-75) (-75) (-75)
				(-75) (-75) (-75) (-75) (-75) (-75) (-75) (-75) (-75) (-75) (-75) (-75) (-75) (-75) (-75) (-75) (-75) (-75) (-75) (-75) (-75) (-75) (-75) (-75) (-75) (-75) (-75) (-75) (-75) (-75) (-75) (-75)
				(-75) (-75) (-75) (-75) (-75) (-75) (-75) (-75) (-75) (-75) (-75) (-75) (-75) (-75) (-75) (-75) (-75) (-75) (-75) (-75) (-75) (-75) (-75) (-75) (-75) (-75) (-75) (-75) (-75) (-75) (-75) (-75)
				(-75) (-75) (-75) (-75) (-75) (-75) (-75) (-75) (-75) (-75) (-75) (-75) (-75) (-75) (-75) (-75) (-75) (-75) (-75) (-75) (-75) (-75) (-75) (-75) (-75) (-75) (-75) (-75) (-75) (-75) (-75) (-75)
				(-75) (-75) (-75) (-75) (-75) (-75) (-75) (-75) (-75) (-75) (-75) (-75) (-75) (-75) (-75) (-75) (-75) (-75) (-75) (-75) (-75) (-75) (-75) (-75) (-75) (-75) (-75) (-75) (-75) (-75) (-75) (-75)
				(-75) (-75) (-75) (-75) (-75) (-75) (-75) (-75) (-75) (-75) (-75) (-75) (-75) (-75) (-75) (-75) (-75) (-75) (-75) (-75) (-75) (-75) (-75) (-75) (-75) (-75) (-75) (-75) (-75) (-75) (-75) (-75)
				(-75) (-75) (-75) (-75) (-75) (-75) (-75) (-75) (-75) (-75) (-75) (-75) (-75) (-75) (-75) (-75) (-75) (-75) (-75) (-75) (-75) (-75) (-75) (-75) (-75) (-75) (-75) (-75) (-75) (-75) (-75) (-75)
				(-75) (-75) (-75) (-75) (-75) (-75) (-75) (-75) (-75) (-75) (-75) (-75) (-75) (-75) (-75) (-75) (-75) (-75) (-75) (-75) (-75) (-75) (-75) (-75) (-75) (-75) (-75) (-75) (-75) (-75) (-75) (-75)
				(-75) (-75) (-75) (-75) (-75) (-75) (-75) (-75) (-75) (-75) (-75) (-75) (-75) (-75) (-75) (-75) (-75) (-75) (-75) (-75) (-75) (-75) (-75) (-75) (-75) (-75) (-75) (-75) (-75) (-75) (-75) (-75)
				(-75) (-75) (-75) (-75) (-75) (-75) (-75) (-75) (-75) (-75) (-75) (-75) (-75) (-75) (-75) (-75) (-75) (-75) (-75) (-75) (-75) (-75) (-75) (-75) (-75) (-75) (-75) (-75) (-75) (-75) (-75) (-75)
				(-75) (-75) (-75) (-75) (-75) (-75) (-75) (-75) (-75) (-75) (-75) (-75) (-75) (-75) (-75) (-75) (-75) (-75) (-75) (-75) (-75) (-75) (-75) (-75) (-75) (-75) (-75) (-75) (-75) (-75) (-75) (-75)
				(-75) (-75) (-75)>;

			PS_Config_Lmt_PenTipX_FW_Raw_P = <
				570 570 570 570 570 570 570 570 570 570 570 570 570 570 570 570 570 570 570 570 570 570 570 570 570 570 570 570 570 570 570 570
				570 570 570 570 570 570 570 570 570 570 570 570 570 570 570 570 570 570 570 570 570 570 570 570 570 570 570 570 570 570 570 570
				570 570 570 570 570 570 570 570 570 570 570 570 570 570 570 570 570 570 570 570 570 570 570 570 570 570 570 570 570 570 570 570
				570 570 570 570 570 570 570 570 570 570 570 570 570 570 570 570 570 570 570 570 570 570 570 570 570 570 570 570 570 570 570 570
				570 570 570 570 570 570 570 570 570 570 570 570 570 570 570 570 570 570 570 570 570 570 570 570 570 570 570 570 570 570 570 570
				570 570 570 570 570 570 570 570 570 570 570 570 570 570 570 570 570 570 570 570 570 570 570 570 570 570 570 570 570 570 570 570>;

			PS_Config_Lmt_PenTipX_FW_Raw_N = <
				(-570) (-570) (-570) (-570) (-570) (-570) (-570) (-570) (-570) (-570) (-570) (-570) (-570) (-570) (-570) (-570) (-570) (-570) (-570) (-570) (-570) (-570) (-570) (-570) (-570) (-570) (-570) (-570) (-570) (-570) (-570) (-570)
				(-570) (-570) (-570) (-570) (-570) (-570) (-570) (-570) (-570) (-570) (-570) (-570) (-570) (-570) (-570) (-570) (-570) (-570) (-570) (-570) (-570) (-570) (-570) (-570) (-570) (-570) (-570) (-570) (-570) (-570) (-570) (-570)
				(-570) (-570) (-570) (-570) (-570) (-570) (-570) (-570) (-570) (-570) (-570) (-570) (-570) (-570) (-570) (-570) (-570) (-570) (-570) (-570) (-570) (-570) (-570) (-570) (-570) (-570) (-570) (-570) (-570) (-570) (-570) (-570)
				(-570) (-570) (-570) (-570) (-570) (-570) (-570) (-570) (-570) (-570) (-570) (-570) (-570) (-570) (-570) (-570) (-570) (-570) (-570) (-570) (-570) (-570) (-570) (-570) (-570) (-570) (-570) (-570) (-570) (-570) (-570) (-570)
				(-570) (-570) (-570) (-570) (-570) (-570) (-570) (-570) (-570) (-570) (-570) (-570) (-570) (-570) (-570) (-570) (-570) (-570) (-570) (-570) (-570) (-570) (-570) (-570) (-570) (-570) (-570) (-570) (-570) (-570) (-570) (-570)
				(-570) (-570) (-570) (-570) (-570) (-570) (-570) (-570) (-570) (-570) (-570) (-570) (-570) (-570) (-570) (-570) (-570) (-570) (-570) (-570) (-570) (-570) (-570) (-570) (-570) (-570) (-570) (-570) (-570) (-570) (-570) (-570)>;

			PS_Config_Lmt_PenTipY_FW_Raw_P = <
				570 570 570 570
				570 570 570 570
				570 570 570 570
				570 570 570 570
				570 570 570 570
				570 570 570 570
				570 570 570 570
				570 570 570 570
				570 570 570 570
				570 570 570 570
				570 570 570 570
				570 570 570 570
				570 570 570 570
				570 570 570 570
				570 570 570 570
				570 570 570 570
				570 570 570 570
				570 570 570 570
				570 570 570 570
				570 570 570 570
				570 570 570 570
				570 570 570 570
				570 570 570 570
				570 570 570 570
				570 570 570 570
				570 570 570 570
				570 570 570 570
				570 570 570 570
				570 570 570 570
				570 570 570 570
				570 570 570 570
				570 570 570 570
				570 570 570 570
				570 570 570 570
				570 570 570 570
				570 570 570 570
				570 570 570 570
				570 570 570 570
				570 570 570 570
				570 570 570 570
				570 570 570 570
				570 570 570 570
				570 570 570 570
				570 570 570 570
				570 570 570 570
				570 570 570 570
				570 570 570 570
				570 570 570 570
				570 570 570 570
				570 570 570 570>;

			PS_Config_Lmt_PenTipY_FW_Raw_N = <
				(-570) (-570) (-570) (-570)
				(-570) (-570) (-570) (-570)
				(-570) (-570) (-570) (-570)
				(-570) (-570) (-570) (-570)
				(-570) (-570) (-570) (-570)
				(-570) (-570) (-570) (-570)
				(-570) (-570) (-570) (-570)
				(-570) (-570) (-570) (-570)
				(-570) (-570) (-570) (-570)
				(-570) (-570) (-570) (-570)
				(-570) (-570) (-570) (-570)
				(-570) (-570) (-570) (-570)
				(-570) (-570) (-570) (-570)
				(-570) (-570) (-570) (-570)
				(-570) (-570) (-570) (-570)
				(-570) (-570) (-570) (-570)
				(-570) (-570) (-570) (-570)
				(-570) (-570) (-570) (-570)
				(-570) (-570) (-570) (-570)
				(-570) (-570) (-570) (-570)
				(-570) (-570) (-570) (-570)
				(-570) (-570) (-570) (-570)
				(-570) (-570) (-570) (-570)
				(-570) (-570) (-570) (-570)
				(-570) (-570) (-570) (-570)
				(-570) (-570) (-570) (-570)
				(-570) (-570) (-570) (-570)
				(-570) (-570) (-570) (-570)
				(-570) (-570) (-570) (-570)
				(-570) (-570) (-570) (-570)
				(-570) (-570) (-570) (-570)
				(-570) (-570) (-570) (-570)
				(-570) (-570) (-570) (-570)
				(-570) (-570) (-570) (-570)
				(-570) (-570) (-570) (-570)
				(-570) (-570) (-570) (-570)
				(-570) (-570) (-570) (-570)
				(-570) (-570) (-570) (-570)
				(-570) (-570) (-570) (-570)
				(-570) (-570) (-570) (-570)
				(-570) (-570) (-570) (-570)
				(-570) (-570) (-570) (-570)
				(-570) (-570) (-570) (-570)
				(-570) (-570) (-570) (-570)
				(-570) (-570) (-570) (-570)
				(-570) (-570) (-570) (-570)
				(-570) (-570) (-570) (-570)
				(-570) (-570) (-570) (-570)
				(-570) (-570) (-570) (-570)
				(-570) (-570) (-570) (-570)>;

			PS_Config_Lmt_PenRingX_FW_Raw_P = <
				570 570 570 570 570 570 570 570 570 570 570 570 570 570 570 570 570 570 570 570 570 570 570 570 570 570 570 570 570 570 570 570
				570 570 570 570 570 570 570 570 570 570 570 570 570 570 570 570 570 570 570 570 570 570 570 570 570 570 570 570 570 570 570 570
				570 570 570 570 570 570 570 570 570 570 570 570 570 570 570 570 570 570 570 570 570 570 570 570 570 570 570 570 570 570 570 570
				570 570 570 570 570 570 570 570 570 570 570 570 570 570 570 570 570 570 570 570 570 570 570 570 570 570 570 570 570 570 570 570
				570 570 570 570 570 570 570 570 570 570 570 570 570 570 570 570 570 570 570 570 570 570 570 570 570 570 570 570 570 570 570 570
				570 570 570 570 570 570 570 570 570 570 570 570 570 570 570 570 570 570 570 570 570 570 570 570 570 570 570 570 570 570 570 570>;

			PS_Config_Lmt_PenRingX_FW_Raw_N = <
				(-570) (-570) (-570) (-570) (-570) (-570) (-570) (-570) (-570) (-570) (-570) (-570) (-570) (-570) (-570) (-570) (-570) (-570) (-570) (-570) (-570) (-570) (-570) (-570) (-570) (-570) (-570) (-570) (-570) (-570) (-570) (-570)
				(-570) (-570) (-570) (-570) (-570) (-570) (-570) (-570) (-570) (-570) (-570) (-570) (-570) (-570) (-570) (-570) (-570) (-570) (-570) (-570) (-570) (-570) (-570) (-570) (-570) (-570) (-570) (-570) (-570) (-570) (-570) (-570)
				(-570) (-570) (-570) (-570) (-570) (-570) (-570) (-570) (-570) (-570) (-570) (-570) (-570) (-570) (-570) (-570) (-570) (-570) (-570) (-570) (-570) (-570) (-570) (-570) (-570) (-570) (-570) (-570) (-570) (-570) (-570) (-570)
				(-570) (-570) (-570) (-570) (-570) (-570) (-570) (-570) (-570) (-570) (-570) (-570) (-570) (-570) (-570) (-570) (-570) (-570) (-570) (-570) (-570) (-570) (-570) (-570) (-570) (-570) (-570) (-570) (-570) (-570) (-570) (-570)
				(-570) (-570) (-570) (-570) (-570) (-570) (-570) (-570) (-570) (-570) (-570) (-570) (-570) (-570) (-570) (-570) (-570) (-570) (-570) (-570) (-570) (-570) (-570) (-570) (-570) (-570) (-570) (-570) (-570) (-570) (-570) (-570)
				(-570) (-570) (-570) (-570) (-570) (-570) (-570) (-570) (-570) (-570) (-570) (-570) (-570) (-570) (-570) (-570) (-570) (-570) (-570) (-570) (-570) (-570) (-570) (-570) (-570) (-570) (-570) (-570) (-570) (-570) (-570) (-570)>;

			PS_Config_Lmt_PenRingY_FW_Raw_P = <
				570 570 570 570
				570 570 570 570
				570 570 570 570
				570 570 570 570
				570 570 570 570
				570 570 570 570
				570 570 570 570
				570 570 570 570
				570 570 570 570
				570 570 570 570
				570 570 570 570
				570 570 570 570
				570 570 570 570
				570 570 570 570
				570 570 570 570
				570 570 570 570
				570 570 570 570
				570 570 570 570
				570 570 570 570
				570 570 570 570
				570 570 570 570
				570 570 570 570
				570 570 570 570
				570 570 570 570
				570 570 570 570
				570 570 570 570
				570 570 570 570
				570 570 570 570
				570 570 570 570
				570 570 570 570
				570 570 570 570
				570 570 570 570
				570 570 570 570
				570 570 570 570
				570 570 570 570
				570 570 570 570
				570 570 570 570
				570 570 570 570
				570 570 570 570
				570 570 570 570
				570 570 570 570
				570 570 570 570
				570 570 570 570
				570 570 570 570
				570 570 570 570
				570 570 570 570
				570 570 570 570
				570 570 570 570
				570 570 570 570
				570 570 570 570>;

			PS_Config_Lmt_PenRingY_FW_Raw_N = <
				(-570) (-570) (-570) (-570)
				(-570) (-570) (-570) (-570)
				(-570) (-570) (-570) (-570)
				(-570) (-570) (-570) (-570)
				(-570) (-570) (-570) (-570)
				(-570) (-570) (-570) (-570)
				(-570) (-570) (-570) (-570)
				(-570) (-570) (-570) (-570)
				(-570) (-570) (-570) (-570)
				(-570) (-570) (-570) (-570)
				(-570) (-570) (-570) (-570)
				(-570) (-570) (-570) (-570)
				(-570) (-570) (-570) (-570)
				(-570) (-570) (-570) (-570)
				(-570) (-570) (-570) (-570)
				(-570) (-570) (-570) (-570)
				(-570) (-570) (-570) (-570)
				(-570) (-570) (-570) (-570)
				(-570) (-570) (-570) (-570)
				(-570) (-570) (-570) (-570)
				(-570) (-570) (-570) (-570)
				(-570) (-570) (-570) (-570)
				(-570) (-570) (-570) (-570)
				(-570) (-570) (-570) (-570)
				(-570) (-570) (-570) (-570)
				(-570) (-570) (-570) (-570)
				(-570) (-570) (-570) (-570)
				(-570) (-570) (-570) (-570)
				(-570) (-570) (-570) (-570)
				(-570) (-570) (-570) (-570)
				(-570) (-570) (-570) (-570)
				(-570) (-570) (-570) (-570)
				(-570) (-570) (-570) (-570)
				(-570) (-570) (-570) (-570)
				(-570) (-570) (-570) (-570)
				(-570) (-570) (-570) (-570)
				(-570) (-570) (-570) (-570)
				(-570) (-570) (-570) (-570)
				(-570) (-570) (-570) (-570)
				(-570) (-570) (-570) (-570)
				(-570) (-570) (-570) (-570)
				(-570) (-570) (-570) (-570)
				(-570) (-570) (-570) (-570)
				(-570) (-570) (-570) (-570)
				(-570) (-570) (-570) (-570)
				(-570) (-570) (-570) (-570)
				(-570) (-570) (-570) (-570)
				(-570) (-570) (-570) (-570)
				(-570) (-570) (-570) (-570)
				(-570) (-570) (-570) (-570)>;

			PS_Config_Lmt_PenTipX_FW_Diff_P = <
				870 870 870 870 870 870 870 870 870 870 870 870 870 870 870 870 870 870 870 870 870 870 870 870 870 870 870 870 870 870 870 870
				870 870 870 870 870 870 870 870 870 870 870 870 870 870 870 870 870 870 870 870 870 870 870 870 870 870 870 870 870 870 870 870
				870 870 870 870 870 870 870 870 870 870 870 870 870 870 870 870 870 870 870 870 870 870 870 870 870 870 870 870 870 870 870 870
				870 870 870 870 870 870 870 870 870 870 870 870 870 870 870 870 870 870 870 870 870 870 870 870 870 870 870 870 870 870 870 870
				870 870 870 870 870 870 870 870 870 870 870 870 870 870 870 870 870 870 870 870 870 870 870 870 870 870 870 870 870 870 870 870
				870 870 870 870 870 870 870 870 870 870 870 870 870 870 870 870 870 870 870 870 870 870 870 870 870 870 870 870 870 870 870 870>;

			PS_Config_Lmt_PenTipX_FW_Diff_N = <
				(-870) (-870) (-870) (-870) (-870) (-870) (-870) (-870) (-870) (-870) (-870) (-870) (-870) (-870) (-870) (-870) (-870) (-870) (-870) (-870) (-870) (-870) (-870) (-870) (-870) (-870) (-870) (-870) (-870) (-870) (-870) (-870)
				(-870) (-870) (-870) (-870) (-870) (-870) (-870) (-870) (-870) (-870) (-870) (-870) (-870) (-870) (-870) (-870) (-870) (-870) (-870) (-870) (-870) (-870) (-870) (-870) (-870) (-870) (-870) (-870) (-870) (-870) (-870) (-870)
				(-870) (-870) (-870) (-870) (-870) (-870) (-870) (-870) (-870) (-870) (-870) (-870) (-870) (-870) (-870) (-870) (-870) (-870) (-870) (-870) (-870) (-870) (-870) (-870) (-870) (-870) (-870) (-870) (-870) (-870) (-870) (-870)
				(-870) (-870) (-870) (-870) (-870) (-870) (-870) (-870) (-870) (-870) (-870) (-870) (-870) (-870) (-870) (-870) (-870) (-870) (-870) (-870) (-870) (-870) (-870) (-870) (-870) (-870) (-870) (-870) (-870) (-870) (-870) (-870)
				(-870) (-870) (-870) (-870) (-870) (-870) (-870) (-870) (-870) (-870) (-870) (-870) (-870) (-870) (-870) (-870) (-870) (-870) (-870) (-870) (-870) (-870) (-870) (-870) (-870) (-870) (-870) (-870) (-870) (-870) (-870) (-870)
				(-870) (-870) (-870) (-870) (-870) (-870) (-870) (-870) (-870) (-870) (-870) (-870) (-870) (-870) (-870) (-870) (-870) (-870) (-870) (-870) (-870) (-870) (-870) (-870) (-870) (-870) (-870) (-870) (-870) (-870) (-870) (-870)>;

			PS_Config_Lmt_PenTipY_FW_Diff_P = <
				870 870 870 870
				870 870 870 870
				870 870 870 870
				870 870 870 870
				870 870 870 870
				870 870 870 870
				870 870 870 870
				870 870 870 870
				870 870 870 870
				870 870 870 870
				870 870 870 870
				870 870 870 870
				870 870 870 870
				870 870 870 870
				870 870 870 870
				870 870 870 870
				870 870 870 870
				870 870 870 870
				870 870 870 870
				870 870 870 870
				870 870 870 870
				870 870 870 870
				870 870 870 870
				870 870 870 870
				870 870 870 870
				870 870 870 870
				870 870 870 870
				870 870 870 870
				870 870 870 870
				870 870 870 870
				870 870 870 870
				870 870 870 870
				870 870 870 870
				870 870 870 870
				870 870 870 870
				870 870 870 870
				870 870 870 870
				870 870 870 870
				870 870 870 870
				870 870 870 870
				870 870 870 870
				870 870 870 870
				870 870 870 870
				870 870 870 870
				870 870 870 870
				870 870 870 870
				870 870 870 870
				870 870 870 870
				870 870 870 870
				870 870 870 870>;

			PS_Config_Lmt_PenTipY_FW_Diff_N = <
				(-870) (-870) (-870) (-870)
				(-870) (-870) (-870) (-870)
				(-870) (-870) (-870) (-870)
				(-870) (-870) (-870) (-870)
				(-870) (-870) (-870) (-870)
				(-870) (-870) (-870) (-870)
				(-870) (-870) (-870) (-870)
				(-870) (-870) (-870) (-870)
				(-870) (-870) (-870) (-870)
				(-870) (-870) (-870) (-870)
				(-870) (-870) (-870) (-870)
				(-870) (-870) (-870) (-870)
				(-870) (-870) (-870) (-870)
				(-870) (-870) (-870) (-870)
				(-870) (-870) (-870) (-870)
				(-870) (-870) (-870) (-870)
				(-870) (-870) (-870) (-870)
				(-870) (-870) (-870) (-870)
				(-870) (-870) (-870) (-870)
				(-870) (-870) (-870) (-870)
				(-870) (-870) (-870) (-870)
				(-870) (-870) (-870) (-870)
				(-870) (-870) (-870) (-870)
				(-870) (-870) (-870) (-870)
				(-870) (-870) (-870) (-870)
				(-870) (-870) (-870) (-870)
				(-870) (-870) (-870) (-870)
				(-870) (-870) (-870) (-870)
				(-870) (-870) (-870) (-870)
				(-870) (-870) (-870) (-870)
				(-870) (-870) (-870) (-870)
				(-870) (-870) (-870) (-870)
				(-870) (-870) (-870) (-870)
				(-870) (-870) (-870) (-870)
				(-870) (-870) (-870) (-870)
				(-870) (-870) (-870) (-870)
				(-870) (-870) (-870) (-870)
				(-870) (-870) (-870) (-870)
				(-870) (-870) (-870) (-870)
				(-870) (-870) (-870) (-870)
				(-870) (-870) (-870) (-870)
				(-870) (-870) (-870) (-870)
				(-870) (-870) (-870) (-870)
				(-870) (-870) (-870) (-870)
				(-870) (-870) (-870) (-870)
				(-870) (-870) (-870) (-870)
				(-870) (-870) (-870) (-870)
				(-870) (-870) (-870) (-870)
				(-870) (-870) (-870) (-870)
				(-870) (-870) (-870) (-870)>;

			PS_Config_Lmt_PenRingX_FW_Diff_P = <
				870 870 870 870 870 870 870 870 870 870 870 870 870 870 870 870 870 870 870 870 870 870 870 870 870 870 870 870 870 870 870 870
				870 870 870 870 870 870 870 870 870 870 870 870 870 870 870 870 870 870 870 870 870 870 870 870 870 870 870 870 870 870 870 870
				870 870 870 870 870 870 870 870 870 870 870 870 870 870 870 870 870 870 870 870 870 870 870 870 870 870 870 870 870 870 870 870
				870 870 870 870 870 870 870 870 870 870 870 870 870 870 870 870 870 870 870 870 870 870 870 870 870 870 870 870 870 870 870 870
				870 870 870 870 870 870 870 870 870 870 870 870 870 870 870 870 870 870 870 870 870 870 870 870 870 870 870 870 870 870 870 870
				870 870 870 870 870 870 870 870 870 870 870 870 870 870 870 870 870 870 870 870 870 870 870 870 870 870 870 870 870 870 870 870>;

			PS_Config_Lmt_PenRingX_FW_Diff_N = <
				(-870) (-870) (-870) (-870) (-870) (-870) (-870) (-870) (-870) (-870) (-870) (-870) (-870) (-870) (-870) (-870) (-870) (-870) (-870) (-870) (-870) (-870) (-870) (-870) (-870) (-870) (-870) (-870) (-870) (-870) (-870) (-870)
				(-870) (-870) (-870) (-870) (-870) (-870) (-870) (-870) (-870) (-870) (-870) (-870) (-870) (-870) (-870) (-870) (-870) (-870) (-870) (-870) (-870) (-870) (-870) (-870) (-870) (-870) (-870) (-870) (-870) (-870) (-870) (-870)
				(-870) (-870) (-870) (-870) (-870) (-870) (-870) (-870) (-870) (-870) (-870) (-870) (-870) (-870) (-870) (-870) (-870) (-870) (-870) (-870) (-870) (-870) (-870) (-870) (-870) (-870) (-870) (-870) (-870) (-870) (-870) (-870)
				(-870) (-870) (-870) (-870) (-870) (-870) (-870) (-870) (-870) (-870) (-870) (-870) (-870) (-870) (-870) (-870) (-870) (-870) (-870) (-870) (-870) (-870) (-870) (-870) (-870) (-870) (-870) (-870) (-870) (-870) (-870) (-870)
				(-870) (-870) (-870) (-870) (-870) (-870) (-870) (-870) (-870) (-870) (-870) (-870) (-870) (-870) (-870) (-870) (-870) (-870) (-870) (-870) (-870) (-870) (-870) (-870) (-870) (-870) (-870) (-870) (-870) (-870) (-870) (-870)
				(-870) (-870) (-870) (-870) (-870) (-870) (-870) (-870) (-870) (-870) (-870) (-870) (-870) (-870) (-870) (-870) (-870) (-870) (-870) (-870) (-870) (-870) (-870) (-870) (-870) (-870) (-870) (-870) (-870) (-870) (-870) (-870)>;

			PS_Config_Lmt_PenRingY_FW_Diff_P = <
				870 870 870 870
				870 870 870 870
				870 870 870 870
				870 870 870 870
				870 870 870 870
				870 870 870 870
				870 870 870 870
				870 870 870 870
				870 870 870 870
				870 870 870 870
				870 870 870 870
				870 870 870 870
				870 870 870 870
				870 870 870 870
				870 870 870 870
				870 870 870 870
				870 870 870 870
				870 870 870 870
				870 870 870 870
				870 870 870 870
				870 870 870 870
				870 870 870 870
				870 870 870 870
				870 870 870 870
				870 870 870 870
				870 870 870 870
				870 870 870 870
				870 870 870 870
				870 870 870 870
				870 870 870 870
				870 870 870 870
				870 870 870 870
				870 870 870 870
				870 870 870 870
				870 870 870 870
				870 870 870 870
				870 870 870 870
				870 870 870 870
				870 870 870 870
				870 870 870 870
				870 870 870 870
				870 870 870 870
				870 870 870 870
				870 870 870 870
				870 870 870 870
				870 870 870 870
				870 870 870 870
				870 870 870 870
				870 870 870 870
				870 870 870 870>;

			PS_Config_Lmt_PenRingY_FW_Diff_N = <
				(-870) (-870) (-870) (-870)
				(-870) (-870) (-870) (-870)
				(-870) (-870) (-870) (-870)
				(-870) (-870) (-870) (-870)
				(-870) (-870) (-870) (-870)
				(-870) (-870) (-870) (-870)
				(-870) (-870) (-870) (-870)
				(-870) (-870) (-870) (-870)
				(-870) (-870) (-870) (-870)
				(-870) (-870) (-870) (-870)
				(-870) (-870) (-870) (-870)
				(-870) (-870) (-870) (-870)
				(-870) (-870) (-870) (-870)
				(-870) (-870) (-870) (-870)
				(-870) (-870) (-870) (-870)
				(-870) (-870) (-870) (-870)
				(-870) (-870) (-870) (-870)
				(-870) (-870) (-870) (-870)
				(-870) (-870) (-870) (-870)
				(-870) (-870) (-870) (-870)
				(-870) (-870) (-870) (-870)
				(-870) (-870) (-870) (-870)
				(-870) (-870) (-870) (-870)
				(-870) (-870) (-870) (-870)
				(-870) (-870) (-870) (-870)
				(-870) (-870) (-870) (-870)
				(-870) (-870) (-870) (-870)
				(-870) (-870) (-870) (-870)
				(-870) (-870) (-870) (-870)
				(-870) (-870) (-870) (-870)
				(-870) (-870) (-870) (-870)
				(-870) (-870) (-870) (-870)
				(-870) (-870) (-870) (-870)
				(-870) (-870) (-870) (-870)
				(-870) (-870) (-870) (-870)
				(-870) (-870) (-870) (-870)
				(-870) (-870) (-870) (-870)
				(-870) (-870) (-870) (-870)
				(-870) (-870) (-870) (-870)
				(-870) (-870) (-870) (-870)
				(-870) (-870) (-870) (-870)
				(-870) (-870) (-870) (-870)
				(-870) (-870) (-870) (-870)
				(-870) (-870) (-870) (-870)
				(-870) (-870) (-870) (-870)
				(-870) (-870) (-870) (-870)
				(-870) (-870) (-870) (-870)
				(-870) (-870) (-870) (-870)
				(-870) (-870) (-870) (-870)
				(-870) (-870) (-870) (-870)>;

			PS_Config_Diff_Test_Frame = <50>;
		};
	};
};

&dvfs_dcdc_cpu0_cfg {
	pmic-type-num = <0>;
	slew-rate = <9375>; /* 9375uV/us */
	tuning-latency-us = <0>;
};

&dvfs_dcdc_cpu1_cfg {
	pmic-type-num = <0>;
	slew-rate = <9375>; /* 9375uV/us */
	supply-type-sel = <0x120 0 0>;
	top-dvfs-adi-state = <0x9c 0 0xf>;
	voltage-grade-num = <8>;
	voltage-grade = <0 0xf0 0x100 0 0x1ff>,
		<1 0x100 0x100 9 0x1ff>,
		<2 0x110 0x100 18 0x1ff>,
		<3 0x120 0x104 0 0x1ff>,
		<4 0x130 0x104 9 0x1ff>,
		<5 0x140 0x104 18 0x1ff>,
		<6 0x140 0x108 0 0x1ff>,
		<7 0x140 0x108 9 0x1ff>;
	voltage-up-delay = <50 0x84 0 0xffff 0x600>,
		<100 0x84 16 0xffff 0xa00>,
		<150 0x80 0 0xffff 0xf00>,
		<200 0x80 16 0xffff 0x1400>,
		<250 0x7c 0 0xffff 0x1900>,
		<300 0x7c 16 0xffff 0x1e00>,
		<350 0x118 0 0xffff 0x2300>;
	voltage-down-delay = <50 0x90 0 0xffff 0x600>,
		<100 0x90 16 0xffff 0xa00>,
		<150 0x8c 0 0xffff 0xf00>,
		<200 0x8c 16 0xffff 0x1400>,
		<250 0x88 0 0xffff 0x1900>,
		<300 0x88 16 0xffff 0x1e00>,
		<350 0x11c 0 0xffff 0x2300>;
	tuning-latency-us = <0>;
	chnl-in-i2c = <0>;
};

&dvfs_dcdc_cpu1_cfg1 {
	third-pmic-used;
	pmic-type-num = <0>;
	slew-rate = <9375>; /* 9375uV/us */
	tuning-latency-us = <0>;
};

&extcon_gpio{
	id-gpio = <&eic_debounce 27 GPIO_ACTIVE_HIGH>;
};

&hsphy {
	vdd-supply = <&vddusb33>;
	extcon = <&extcon_gpio>;
	sprd,hsphy-device-eye-pattern = <0x293d1c0>;
	sprd,hsphy-host-eye-pattern = <0x2b3d1c0>;
	io-channels = <&pmic_adc 30>, <&pmic_adc 31>;
	io-channel-names = "dp", "dm";
	status = "okay";
};

&usb {
	extcon = <&extcon_gpio>;
	vbus-supply = <&vddvbus>;
	status = "okay";
};

&sdio0 {
	cd-gpios = <&eic_sync 35 GPIO_ACTIVE_HIGH>;
};

&vddsim2 {
	regulator-always-on;
};


&sdio1 {
	sprd,phy-delay-sd-uhs-sdr104 = <0x7f 0x7f 0x7f 0x7f>;
	sprd,phy-delay-sd-uhs-sdr50 = <0x7f 0x7f 0x8f 0x8f>;
	sd-uhs-sdr104;
	sd-uhs-sdr50;
	bus-width = <4>;
	sprd,name = "sdio_wifi";
	sprd,sdio-adma;
	no-sd;
	no-mmc;
	status = "okay";
};

&i2c2 {
    status = "okay";
};

&i2c3 {
    status = "okay";
};

&i2c4 {
    status = "okay";
};

&aon_i2c0 {
	status = "okay";
	clock-frequency = <1000000>;
};

&vdd28 {
    regulator-name = "vdd28";
    regulator-min-microvolt = <3000000>;
    regulator-max-microvolt = <3000000>;
    regulator-always-on;
};

&sprd_headset {
    status = "okay";
};

&pdm_dmic {
	status = "okay";
};

&sound_vbc_v4_sprd_codec {
	status = "okay";
	/*ext_control_type, hook selection, mode, gpio share*/
	sprd,spk-ext-pa-info = <0 1 2 0>;
	sprd,spk-ext-pa-gpio = <&ap_gpio 167 0>;
};



&vddldo0 {
	regulator-always-on;
};

&pmic_fgu {
	monitored-battery = <&bat &bat1 &nbat>;
	sprd,calib-resistance-micro-ohms = <10000>;
	sprd,comp-resistance-mohm = <8>;

	fgu-capacity-track;
	phys = <&hsphy>;
	io-channels = <&pmic_adc 0>, <&pmic_adc 14>, <&pmic_adc 6>;
	io-channel-names = "bat-temp", "charge-vol", "bat-id-vol";
};

&panel {
	avdd-gpio = <&ap_gpio 135 GPIO_ACTIVE_HIGH>;
	avee-gpio = <&ap_gpio 136 GPIO_ACTIVE_HIGH>;
	reset-gpio = <&ap_gpio 50 GPIO_ACTIVE_HIGH>;
};

&dpu {
	sprd,logo-memory = <&logo_reserved>;
};

&pmic_fchg {
	status = "disable";
	sprd,input-voltage-microvolt = <5000000>;
	sprd,pd-fixed-max-microwatt = <18000000>;
	sprd,support-sfcp;
	sprd,support-pd-pps;
	phys = <&hsphy>;
};

&pmic_pd {
	status = "disable";
	usb_con: connector {
		compatible = "usb-c-connector";
		label = "USB-C";
		power-role = "dual";
		try-power-role = "sink";
		source-pdos = <PDO_FIXED(5000, 400, PDO_FIXED_USB_COMM)>;
		sink-pdos = <PDO_FIXED(5000, 3000, PDO_FIXED_USB_COMM)
			     PDO_PPS_APDO(3300, 11000, 3000)>;
		op-sink-microwatt = <10000000>;
	};
};

&ddr_dfs {
	  sprd-scene = "boost", "lcdon", "lcdoff", "camlow",
			"camhigh", "camveryhigh", "faceid", "top";
	  sprd-freq = <1333 768 256 1333 1333 0xbacd 1333 0xbacd>;
};

&pin_controller {
	pinctrl-names =
	/* rfctl16 ,rfctl3, rfctl5 */
	"gpio_8", "gpio_22", "gpio_24",
	/* rfctl6, rfctl7, keyin0 */
	"gpio_25", "gpio_26", "gpio_124",
	/* bt_rfctl2 */
	"gpio_175";
	pinctrl-0 = <&gpio_8>;
	pinctrl-1 = <&gpio_22>;
	pinctrl-2 = <&gpio_24>;
	pinctrl-3 = <&gpio_25>;
	pinctrl-4 = <&gpio_26>;
	pinctrl-5 = <&gpio_124>;
	pinctrl-6 = <&gpio_175>;

	gpio_8: rfctl16 {
		pins = "QOGIRL6_RFCTL16";
		function = "func4";
	};

	gpio_22: rfctl3 {
		pins = "QOGIRL6_RFCTL3";
		function = "func4";
	};

	gpio_24: rfctl5 {
		pins = "QOGIRL6_RFCTL5";
		function = "func4";
	};

	gpio_25: rfctl6 {
		pins = "QOGIRL6_RFCTL6";
		function = "func4";
	};

	gpio_26: rfctl7 {
		pins = "QOGIRL6_RFCTL7";
		function = "func4";
	};

	gpio_124: keyin0 {
		pins = "QOGIRL6_KEYIN0";
		function = "func4";
	};

	gpio_175: bt_rfctl2 {
		pins = "QOGIRL6_BT_RFCTL2";
		function = "func4";
	};

	gpio_70_f0:TXD1new {
		pins = "QOGIRL6_U1TXD";
		function = "func1";
	};

	gpio_71_f0:RXD1new {
		pins = "QOGIRL6_U1RXD";
		function = "func1";
	};

	gpio_70_f3:gpi70 {
		pins = "QOGIRL6_U1TXD";
		function = "func4";
	};

	gpio_71_f3:gpio71 {
		pins = "QOGIRL6_U1RXD";
		function = "func4";
	};
};

&ion {
	#address-cells = <1>;
	#size-cells = <0>;

	heap@4 {
		reg = <4>;
		label = "carveout_fd";
		type = <2>;
		memory-region = <&fd_reserved>;
	};
};

&adi_bus {
	sprd,hw-channels0 = <2 0x18cc>, <3 0x18cc>, <13 0x1874>, <15 0x1874>,
			<17 0x1844>, <19 0x1854>, <21 0x1864>, <30 0x1820>,
			<32 0x197c>, <33 0x1988>, <35 0x19b8>, <39 0x19ac>;
	sprd,hw-channels1 = <2 0x18cc>, <3 0x18cc>, <13 0x1854>, <15 0x1874>,
			<17 0x1844>, <19 0x1844>, <21 0x1864>, <30 0x1820>,
			<32 0x197c>, <33 0x1988>, <35 0x19b8>, <39 0x19ac>;
};
